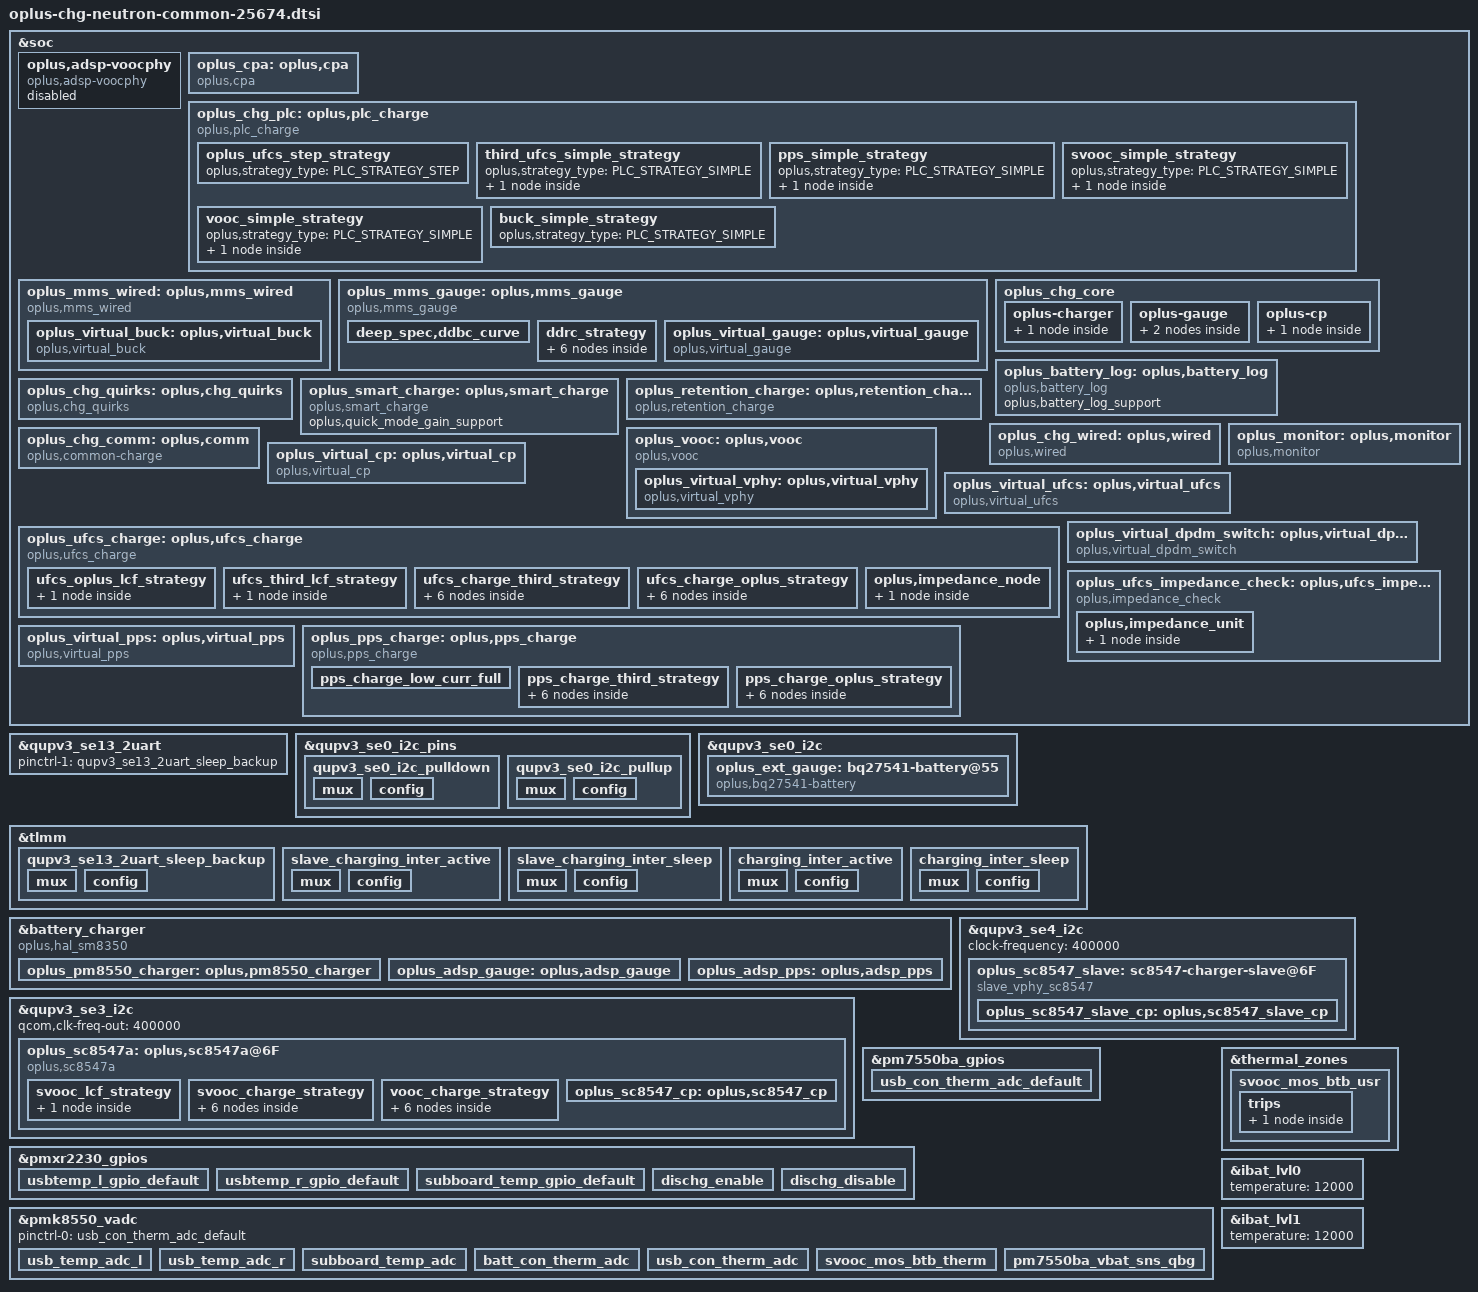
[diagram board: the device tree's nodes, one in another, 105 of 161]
//ifdef OPLUS_FEATURE_CHG_BASIC
#include "../oplus-chg-8750.h.dtsi"
#include <dt-bindings/iio/qcom,spmi-adc5-gen3-pm7550ba.h>
#include <dt-bindings/iio/qcom,spmi-adc5-gen3-pmxr2230.h>

&soc {
	oplus,adsp-voocphy {
		status = "disabled";
		compatible = "oplus,adsp-voocphy";
	};

	oplus_cpa: oplus,cpa {
		compatible = "oplus,cpa";
		oplus,protocol_list = <CHG_PROTOCOL_VOOC 80
				CHG_PROTOCOL_PPS  33
				CHG_PROTOCOL_PD   15
				CHG_PROTOCOL_QC   15>;
		oplus,default_protocol_list = <CHG_PROTOCOL_VOOC
					CHG_PROTOCOL_PPS
					CHG_PROTOCOL_PD>;
	};

	oplus_chg_plc: oplus,plc_charge {
		compatible = "oplus,plc_charge";
		oplus,plc_soc = <90>;
		oplus,plc_strategy-data = <&buck_simple_strategy>;
		oplus,plc_strategy-names = "default";

		oplus_ufcs_step_strategy: oplus_ufcs_step_strategy {
			oplus,strategy_type = <PLC_STRATEGY_STEP>;
		};

		third_ufcs_simple_strategy: third_ufcs_simple_strategy {
			oplus,strategy_type = <PLC_STRATEGY_SIMPLE>;
			oplus,strategy_data {
				strategy_curr_ma = <1000 1500>;
			};
		};

		pps_simple_strategy: pps_simple_strategy {
			oplus,strategy_type = <PLC_STRATEGY_SIMPLE>;
			oplus,strategy_data {
				strategy_curr_ma = <1000 1500>;
			};
		};

		svooc_simple_strategy: svooc_simple_strategy {
			oplus,strategy_type = <PLC_STRATEGY_SIMPLE>;
			oplus,strategy_data {
				strategy_curr_ma = <1000 1500>;
			};
		};

		vooc_simple_strategy: vooc_simple_strategy {
			oplus,strategy_type = <PLC_STRATEGY_SIMPLE>;
			oplus,strategy_data {
				strategy_curr_ma = <2000 3000>;
			};
		};


		buck_simple_strategy: buck_simple_strategy {
			oplus,strategy_type = <PLC_STRATEGY_SIMPLE>;
		};
	};

	oplus_mms_wired: oplus,mms_wired {
		compatible = "oplus,mms_wired";
		oplus,buck_ic = <&oplus_virtual_buck>;
		oplus,voocphy_ic = <&oplus_virtual_vphy>;
		oplus,adc_info_name = "855";
		oplus,topic-update-interval = <5000>;
		high-temp-scheme;
		oplus,otg_cc_limit = <80 2000     /* 100~80 >=80 2A   */
		                      20 1500     /* 80~20  >=20 1.5A */
		                      1  1300>;   /* 20~1   >=1  1.3A */
		oplus,support_usbtemp_protect_v2;
		oplus_spec,usbtemp_batt_temp_low = <50>;
		oplus_spec,usbtemp_batt_temp_high = <50>;
		oplus_spec,usbtemp_batt_temp_over_hot = <60>;
		oplus_spec,usbtemp_ntc_temp_low = <57>;
		oplus_spec,usbtemp_ntc_temp_high = <69>;
		oplus_spec,usbtemp_temp_gap_low_with_batt_temp = <7>;
		oplus_spec,usbtemp_temp_gap_with_batt_temp_in_over_hot = <15>;
		oplus_spec,usbtemp_temp_gap_high_with_batt_temp = <12>;
		oplus_spec,usbtemp_temp_gap_low_without_batt_temp = <12>;
		oplus_spec,usbtemp_temp_gap_high_without_batt_temp = <24>;
		oplus_spec,usbtemp_rise_fast_temp_low = <3>;
		oplus_spec,usbtemp_rise_fast_temp_high = <3>;
		oplus_spec,usbtemp_rise_fast_temp_count_low = <30>;
		oplus_spec,usbtemp_rise_fast_temp_count_high = <20>;
		oplus_spec,usbtemp_cool_down_ntc_low = <54>;
		oplus_spec,usbtemp_cool_down_ntc_high = <65>;
		oplus_spec,usbtemp_cool_down_gap_low = <12>;
		oplus_spec,usbtemp_cool_down_gap_high = <20>;
		oplus_spec,usbtemp_cool_down_recover_ntc_low = <48>;
		oplus_spec,usbtemp_cool_down_recover_ntc_high = <60>;
		oplus_spec,usbtemp_cool_down_recover_gap_low = <6>;
		oplus_spec,usbtemp_cool_down_recover_gap_high = <15>;
		oplus_spec,usbtemp_otg_cc_boot_current_limit = <2000>;

		oplus_virtual_buck: oplus,virtual_buck {
			compatible = "oplus,virtual_buck";
			oplus,buck_ic = <&oplus_pm8550_charger>;
			oplus,buck_ic_index = <0>;
			oplus,buck_ic_connect = <OPLUS_CHG_IC_CONNECT_PARALLEL>;
			oplus,main_charger = <0>;
			oplus,buck_ic_current_ratio = <100>;
			oplus,buck_ic_func_group = <&plat_pm8550_groups>;

			oplus,ic_type = <OPLUS_CHG_IC_VIRTUAL_BUCK>;
			oplus,ic_index = <0>;

			oplus,dischg-gpio = <&pmxr2230_gpios 9 0x00>;
			oplus,usbtemp_conversion_ratio = <10>;

			pinctrl-names = "usbtemp_l_gpio_default", "usbtemp_r_gpio_default",
					"dischg_enable", "dischg_disable";
			pinctrl-0 = <&usbtemp_l_gpio_default>;
			pinctrl-1 = <&usbtemp_r_gpio_default>;
			pinctrl-2 = <&dischg_enable>;
			pinctrl-3 = <&dischg_disable>;

			io-channels = <&pmk8550_vadc PMXR2230_ADC5_GEN3_AMUX1_GPIO3_100K_PU>,
					<&pmk8550_vadc PMXR2230_ADC5_GEN3_AMUX2_GPIO4_100K_PU>;
			io-channel-names = "usb_temp_adc_l", "usb_temp_adc_r";

			oplus,uart_tx-gpio = <&tlmm 18 0x00>;
			oplus,uart_rx-gpio = <&tlmm 19 0x00>;
		};
	};

	oplus_mms_gauge: oplus,mms_gauge {
		compatible = "oplus,mms_gauge";
		oplus,gauge_ic = <&oplus_virtual_gauge>;
		oplus,voocphy_ic = <&oplus_virtual_vphy>;
		oplus,topic-update-interval = <5000>;
		oplus,support_subboard_ntc;

		deep_spec,support;
		deep_spec,uv_thr = <3000>;
		deep_spec,count_thr = <50>;
		deep_spec,vbat_soc = <20>;
		deep_spec,count_step = <0 10 0
					350 12 1
					450 15 2
					530 20 3>;

		deep_spec,term_coeff = <3000 320 0
					3050 440 2
					3060 440 2
					3100 540 4
					3200 580 5
					3300 600 7>;
		deep_spec,ddrc_strategy_name = "ddrc_curve";
		deep_spec,volt_step = <20>;
		deep_spec,ddbc_curve {
			oplus,temp_type = <OPLUS_STRATEGY_USE_BATT_TEMP>;
			oplus,temp_range = <(-100) 50 200>;
			deep_spec,ddbc_temp_cold = <500 3250 5
						   10000 3200 2>;
			deep_spec,ddbc_temp_cool = <500 3250 5
						   10000 3200 2>;
			deep_spec,ddbc_temp_normal = <500 3350 5
						   10000 3300 2>;
			deep_spec,ddbc_temp_warm = <500 3350 5
						   10000 3300 2>;
		};

		ddrc_strategy {
			oplus,temp_type = <OPLUS_STRATEGY_USE_BATT_TEMP>;
			oplus,ratio_range = <20 30 50 70 90>;
			oplus,temp_range = <(-50) 100 350>;
			strategy_ratio_range_min {
				strategy_temp_cold =	<0 3000 3060 0
							400 3000 3060 1
							800 3000 3060 2
							1200 3100 3100 3
							1600 3200 3200 4
							2000 3300 3300 5>;
				strategy_temp_cool =	<0 3000 3060 0
							15   3000 3060 1
							500  3000 3060 2
							1000 3100 3100 3
							1500 3200 3200 4
							2000 3300 3300 5>;
				strategy_temp_normal =	<0 3100 3100 0
							15   3000 3060 1
							500  3100 3100 2
							1000 3200 3200 3
							1500 3300 3300 4>;
				strategy_temp_warm =	<0 3100 3100 0
							15   3000 3060 1
							500  3100 3100 2
							1000 3200 3200 3
							1500 3300 3300 4>;
			};
			strategy_ratio_range_low {
				strategy_temp_cold =	<0 3000 3060 0
							300 3000 3060 1
							600 3000 3060 2
							900 3100 3100 3
							1200 3200 3200 4
							1600 3300 3300 5>;
				strategy_temp_cool =	<0 3000 3060 0
							15   3000 3060 1
							400  3000 3060 2
							800  3100 3100 3
							1200 3200 3200 4
							1600 3300 3300 5>;
				strategy_temp_normal =	<0 3100 3100 0
							15   3000 3060 1
							400  3100 3100 2
							800  3200 3200 3
							1200 3300 3300 4>;
				strategy_temp_warm =	<0 3100 3100 0
							15   3000 3060 1
							400  3100 3100 2
							800  3200 3200 3
							1200 3300 3300 4>;
			};
			strategy_ratio_range_mid_low {
				strategy_temp_cold =	<0 3000 3060 0
							200   3000 3060 1
							400  3100 3060 2
							600  3100 3100 3
							900 3200 3200 4
							1200 3300 3300 5>;
				strategy_temp_cool =	<0 3000 3060 0
							15   3000 3060 1
							300  3000 3060 2
							600  3100 3100 3
							900  3200 3200 4
							1200 3300 3300 5>;
				strategy_temp_normal =	<0 3100 3100 0
							15  3100 3100 1
							300 3100 3100 2
							600 3200 3200 3
							900 3300 3300 4>;
				strategy_temp_warm =	<0 3100 3100 0
							15  3100 3100 1
							300 3100 3100 2
							600 3200 3200 3
							900 3300 3300 4>;
			};
			strategy_ratio_range_mid {
				strategy_temp_cold =	<0 3000 3060 0
							100   3000 3060 1
							300  3000 3060 2
							500  3100 3100 3
							700 3200 3200 4
							900 3300 3300 5>;
				strategy_temp_cool =	<0 3000 3060 0
							100 3000 3060 1
							300 3100 3100 2
							600 3200 3200 3
							900 3300 3300 4>;
				strategy_temp_normal =	<0 3100 3100 0
							100 3100 3100 1
							300 3200 3200 2
							600 3300 3300 3>;
				strategy_temp_warm =	<0 3100 3100 0
							100 3100 3100 1
							300 3200 3200 2
							600 3300 3300 3>;
			};
			strategy_ratio_range_mid_high {
				strategy_temp_cold =	<0 3000 3060 0
							50  3000 3060 1
							100 3000 3060 2
							150 3100 3100 3
							300 3200 3200 4
							500 3300 3300 5>;
				strategy_temp_cool =	<0 3000 3060 0
							50  3000 3060 1
							100 3100 3100 2
							150 3200 3200 3
							300 3300 3300 4>;
				strategy_temp_normal =	<0 3100 3100 0
							50  3100 3100 1
							100 3200 3200 2
							150 3300 3300 3>;
				strategy_temp_warm =	<0 3100 3100 0
							50  3100 3100 1
							100 3200 3200 2
							150 3300 3300 3>;
			};
			strategy_ratio_range_high {
				strategy_temp_cold =	<0 3000 3060 0
                                                        50  3000 3060 1
                                                        100 3000 3060 2
                                                        150 3100 3100 3
                                                        300 3200 3200 4
                                                        500 3300 3300 5>;
				strategy_temp_cool =	<0 3000 3060 0
							50  3000 3060 1
							100 3100 3100 2
							150 3200 3200 3
							300 3300 3300 4>;
				strategy_temp_normal =	<0 3100 3100 0
							50  3100 3100 1
							100 3200 3200 2
							150 3300 3300 3>;
				strategy_temp_warm =	<0 3100 3100 0
							50  3100 3100 1
							100 3200 3200 2
							150 3300 3300 3>;
			};
		};

		oplus_virtual_gauge: oplus,virtual_gauge {
			compatible = "oplus,virtual_gauge";
			oplus,gauge_ic = <&oplus_ext_gauge &oplus_adsp_gauge>;
			oplus,gauge_ic_index = <0 1>;
			oplus,gauge_ic_func_group = <&bq27541_groups &adsp_gauge_groups>;
			oplus,batt_capacity_mah = <7000>;
			oplus,ic_type = <OPLUS_CHG_IC_VIRTUAL_GAUGE>;
			oplus,ic_index = <0>;
		};
	};

	oplus_chg_core: oplus_chg_core {
		oplus,chg_framework_v2;
		oplus,battery_type_by_smem;
		oplus,smart_charging_screenoff;
		oplus,chg_spec_version = <OPLUS_CHG_SPEC_VER_V3P7>;
		oplus,eco_region_list = /bits/ 8 <0x44>;
		oplus,common-charge-icl-support;

		oplus-charger {
			plat_pm8550_groups: oplus,plat_pm8550-groups {
				functions = <
					OPLUS_IC_FUNC_INIT
					OPLUS_IC_FUNC_EXIT
					OPLUS_IC_FUNC_REG_DUMP
					OPLUS_IC_FUNC_SMT_TEST
					OPLUS_IC_FUNC_BUCK_INPUT_PRESENT
					OPLUS_IC_FUNC_BUCK_INPUT_SUSPEND
					OPLUS_IC_FUNC_BUCK_INPUT_IS_SUSPEND
					OPLUS_IC_FUNC_BUCK_OUTPUT_SUSPEND
					OPLUS_IC_FUNC_BUCK_OUTPUT_IS_SUSPEND
					OPLUS_IC_FUNC_BUCK_GET_CC_ORIENTATION
					OPLUS_IC_FUNC_BUCK_GET_CHARGER_TYPE
					OPLUS_IC_FUNC_BUCK_RERUN_BC12
					OPLUS_IC_FUNC_BUCK_QC_DETECT_ENABLE
					OPLUS_IC_FUNC_BUCK_SHIPMODE_ENABLE
					OPLUS_IC_FUNC_BUCK_SET_QC_CONFIG
					OPLUS_IC_FUNC_BUCK_SET_PD_CONFIG
					OPLUS_IC_FUNC_GET_SHUTDOWN_SOC
					OPLUS_IC_FUNC_BACKUP_SOC
					OPLUS_IC_FUNC_GET_TYPEC_MODE
					OPLUS_IC_FUNC_BUCK_SET_ICL
					OPLUS_IC_FUNC_BUCK_GET_ICL
					OPLUS_IC_FUNC_BUCK_SET_FCC
					OPLUS_IC_FUNC_BUCK_SET_FV
					OPLUS_IC_FUNC_BUCK_SET_ITERM
					OPLUS_IC_FUNC_BUCK_SET_RECHG_VOL
					OPLUS_IC_FUNC_BUCK_GET_INPUT_CURR
					OPLUS_IC_FUNC_BUCK_GET_INPUT_VOL
					OPLUS_IC_FUNC_GET_CHARGER_CYCLE
					OPLUS_IC_FUNC_OTG_BOOST_ENABLE
					OPLUS_IC_FUNC_SET_OTG_BOOST_CURR_LIMIT
					OPLUS_IC_FUNC_SET_OTG_SRC_PDO
					OPLUS_IC_FUNC_BUCK_GET_VBUS_COLLAPSE_STATUS
					OPLUS_IC_FUNC_GET_OTG_ENABLE
					OPLUS_IC_FUNC_SET_OTG_SWITCH_STATUS
					OPLUS_IC_FUNC_GET_OTG_SWITCH_STATUS
					OPLUS_IC_FUNC_GET_OTG_ONLINE_STATUS
					OPLUS_IC_FUNC_BUCK_GET_HW_DETECT
					OPLUS_IC_FUNC_VOOCPHY_SET_MATCH_TEMP
					OPLUS_IC_FUNC_IS_OPLUS_SVID
					OPLUS_IC_FUNC_BUCK_SET_VINDPM
					OPLUS_IC_FUNC_BUCK_DIS_INSERT_DETECT
					OPLUS_IC_FUNC_GET_TYPEC_ROLE
					OPLUS_IC_FUNC_SET_TYPEC_MODE
					OPLUS_IC_FUNC_BUCK_GET_USB_BTB_TEMP
					OPLUS_IC_FUNC_BUCK_GET_BATT_BTB_TEMP
					OPLUS_IC_FUNC_BUCK_GET_TYPEC_STATE
				>;
				virqs = <
					OPLUS_IC_VIRQ_ERR
					OPLUS_IC_VIRQ_CC_DETECT
					OPLUS_IC_VIRQ_PLUGIN
					OPLUS_IC_VIRQ_CC_CHANGED
					OPLUS_IC_VIRQ_SUSPEND_CHECK
					OPLUS_IC_VIRQ_CHG_TYPE_CHANGE
					OPLUS_IC_VIRQ_OTG_ENABLE
					OPLUS_IC_VIRQ_SVID
				>;
			};
		};

		oplus-gauge {
			bq27541_groups: oplus,bq27541_groups {
				functions = <
					OPLUS_IC_FUNC_INIT
					OPLUS_IC_FUNC_EXIT
					OPLUS_IC_FUNC_REG_DUMP
					OPLUS_IC_FUNC_SMT_TEST
					OPLUS_IC_FUNC_GAUGE_GET_BATT_VOL
					OPLUS_IC_FUNC_GAUGE_GET_BATT_MAX
					OPLUS_IC_FUNC_GAUGE_GET_BATT_MIN
					OPLUS_IC_FUNC_GAUGE_GET_BATT_CURR
					OPLUS_IC_FUNC_GAUGE_GET_BATT_TEMP
					OPLUS_IC_FUNC_GAUGE_GET_BATT_SOC
					OPLUS_IC_FUNC_GAUGE_GET_BATT_FCC
					OPLUS_IC_FUNC_GAUGE_GET_BATT_CC
					OPLUS_IC_FUNC_GAUGE_GET_BATT_RM
					OPLUS_IC_FUNC_GAUGE_GET_BATT_SOH
					OPLUS_IC_FUNC_GAUGE_GET_BATT_AUTH
					OPLUS_IC_FUNC_GAUGE_GET_BATT_HMAC
					OPLUS_IC_FUNC_GAUGE_SET_BATT_FULL
					OPLUS_IC_FUNC_GAUGE_UPDATE_DOD0
					OPLUS_IC_FUNC_GAUGE_UPDATE_SOC_SMOOTH
					OPLUS_IC_FUNC_GAUGE_GET_CB_STATUS
					OPLUS_IC_FUNC_GAUGE_GET_BATT_NUM
					OPLUS_IC_FUNC_GAUGE_GET_DEVICE_TYPE
					OPLUS_IC_FUNC_GAUGE_GET_DEVICE_TYPE_FOR_VOOC
					OPLUS_IC_FUNC_GAUGE_GET_BATT_FCC
					OPLUS_IC_FUNC_GAUGE_GET_BATT_FC
					OPLUS_IC_FUNC_GAUGE_GET_BATT_QM
					OPLUS_IC_FUNC_GAUGE_GET_BATT_PD
					OPLUS_IC_FUNC_GAUGE_GET_BATT_RCU
					OPLUS_IC_FUNC_GAUGE_GET_BATT_RCF
					OPLUS_IC_FUNC_GAUGE_GET_BATT_FCU
					OPLUS_IC_FUNC_GAUGE_GET_BATT_FCF
					OPLUS_IC_FUNC_GAUGE_GET_BATT_SOU
					OPLUS_IC_FUNC_GAUGE_GET_BATT_DO0
					OPLUS_IC_FUNC_GAUGE_GET_BATT_DOE
					OPLUS_IC_FUNC_GAUGE_GET_BATT_TRM
					OPLUS_IC_FUNC_GAUGE_GET_BATT_PC
					OPLUS_IC_FUNC_GAUGE_GET_BATT_QS
					OPLUS_IC_FUNC_GAUGE_IS_SUSPEND
					OPLUS_IC_FUNC_GAUGE_GET_BCC_PARMS
					OPLUS_IC_FUNC_GAUGE_FASTCHG_UPDATE_BCC_PARMS
					OPLUS_IC_FUNC_GAUGE_GET_PREV_BCC_PARMS
					OPLUS_IC_FUNC_GAUGE_SET_BCC_PARMS
					OPLUS_IC_FUNC_GAUGE_SET_PROTECT_CHECK
					OPLUS_IC_FUNC_GAUGE_GET_AFI_UPDATE_DONE
					OPLUS_IC_FUNC_GAUGE_CHECK_RESET
					OPLUS_IC_FUNC_GAUGE_SET_RESET
					OPLUS_IC_FUNC_GAUGE_GET_DEVICE_TYPE_FOR_BCC
					OPLUS_IC_FUNC_GAUGE_GET_DOD0
					OPLUS_IC_FUNC_GAUGE_GET_DOD0_PASSED_Q
					OPLUS_IC_FUNC_GAUGE_GET_QMAX
					OPLUS_IC_FUNC_GAUGE_GET_QMAX_PASSED_Q
					OPLUS_IC_FUNC_GAUGE_GET_REG_INFO
					OPLUS_IC_FUNC_GAUGE_GET_CALIB_TIME
					OPLUS_IC_FUNC_GAUGE_GET_DEEP_DISCHG_COUNT
					OPLUS_IC_FUNC_GAUGE_SET_DEEP_DISCHG_COUNT
					OPLUS_IC_FUNC_GAUGE_GET_DEEP_TERM_VOLT
					OPLUS_IC_FUNC_GAUGE_SET_DEEP_TERM_VOLT
					OPLUS_IC_FUNC_GAUGE_SET_SILI_SPARE_POWER
					OPLUS_IC_FUNC_GAUGE_GET_SILI_SIMULATE_TERM_VOLT
					OPLUS_IC_FUNC_GAUGE_GET_SILI_IC_ALG_TERM_VOLT
					OPLUS_IC_FUNC_GAUGE_SET_SILI_IC_ALG_CFG
					OPLUS_IC_FUNC_GAUGE_GET_SILI_IC_ALG_DSG_ENABLE
					OPLUS_IC_FUNC_GAUGE_SET_SILI_IC_ALG_TERM_VOLT
					OPLUS_IC_FUNC_GAUGE_GET_SILI_ALG_APPLICATION_INFO
					OPLUS_IC_FUNC_GAUGE_GET_SILI_LIFETIME_STATUS
					OPLUS_IC_FUNC_GAUGE_GET_SILI_LIFETIME_INFO
					OPLUS_IC_FUNC_GAUGE_SET_LAST_CC
					OPLUS_IC_FUNC_GAUGE_GET_LAST_CC
					OPLUS_IC_FUNC_GAUGE_GET_CHEM_ID
					OPLUS_IC_FUNC_GAUGE_GET_DEC_FG_TYPE
					OPLUS_IC_FUNC_GAUGE_GET_DEC_CV_SOH
					OPLUS_IC_FUNC_GAUGE_SET_VCT
					OPLUS_IC_FUNC_GAUGE_GET_VCT
				>;
				virqs = <
					OPLUS_IC_VIRQ_ERR
					OPLUS_IC_VIRQ_OFFLINE
					OPLUS_IC_VIRQ_RESUME
				>;
			};
			adsp_gauge_groups: oplus,gauge_groups {
				functions = <
					OPLUS_IC_FUNC_INIT
					OPLUS_IC_FUNC_EXIT
					OPLUS_IC_FUNC_REG_DUMP
					OPLUS_IC_FUNC_SMT_TEST
					OPLUS_IC_FUNC_GAUGE_GET_SUBBOARD_TEMP
				>;
				virqs = <
					OPLUS_IC_VIRQ_ERR
				>;
			};
		};

		oplus-cp {
			sc8547_cp_groups: oplus,cp_groups {
			functions = <
					OPLUS_IC_FUNC_INIT
					OPLUS_IC_FUNC_EXIT
					OPLUS_IC_FUNC_REG_DUMP
					OPLUS_IC_FUNC_SMT_TEST
					OPLUS_IC_FUNC_CP_ENABLE
					OPLUS_IC_FUNC_CP_HW_INTI
					OPLUS_IC_FUNC_CP_SET_WORK_START
					OPLUS_IC_FUNC_CP_CHECK_WORK_MODE_SUPPORT
					OPLUS_IC_FUNC_CP_SET_WORK_MODE
					OPLUS_IC_FUNC_CP_GET_WORK_MODE
					OPLUS_IC_FUNC_CP_GET_VIN
					OPLUS_IC_FUNC_CP_GET_IIN
					OPLUS_IC_FUNC_CP_SET_IIN
					OPLUS_IC_FUNC_CP_GET_VOUT
					OPLUS_IC_FUNC_CP_GET_IOUT
					OPLUS_IC_FUNC_CP_GET_VAC
					OPLUS_IC_FUNC_CP_GET_WORK_STATUS
					OPLUS_IC_FUNC_CP_SET_ADC_ENABLE
					OPLUS_IC_FUNC_CP_WATCHDOG_ENABLE
				>;
				virqs = <
					OPLUS_IC_VIRQ_ERR
					OPLUS_IC_VIRQ_ONLINE
					OPLUS_IC_VIRQ_OFFLINE
				>;
			};
		};
	};

	oplus_battery_log: oplus,battery_log {
		compatible = "oplus,battery_log";

		oplus,battery_log_support;
	};

	oplus_chg_quirks: oplus,chg_quirks {
		compatible = "oplus,chg_quirks";
	};

	oplus_smart_charge: oplus,smart_charge {
		compatible = "oplus,smart_charge";
		oplus,quick_mode_gain_support;
	};

	oplus_retention_charge: oplus,retention_charge {
		compatible = "oplus,retention_charge";
		oplus,topic-update-interval = <5000>;
		oplus,support_retention_name = "oplus_retention_quirks";
	};

	oplus_chg_wired: oplus,wired {
		compatible = "oplus,wired";

		oplus,vooc-support;

		oplus_spec,vbatt_pdqc_to_5v_thr = <5100>;
		oplus_spec,vbatt_pdqc_to_9v_thr = <5000>;
		oplus_spec,pd-iclmax-ma = <1500>;
		oplus_spec,qc-iclmax-ma = <1500>;
		oplus_spec,non-standard-ibatmax-ma = <500>;
		oplus_spec,input-power-mw = <
			2500		/* OPLUS_WIRED_CHG_MODE_UNKNOWN */
			2500		/* OPLUS_WIRED_CHG_MODE_SDP */
			7500		/* OPLUS_WIRED_CHG_MODE_CDP */
			10000		/* OPLUS_WIRED_CHG_MODE_DCP */
			15000		/* OPLUS_WIRED_CHG_MODE_VOOC */
			13500		/* OPLUS_WIRED_CHG_MODE_QC */
			13500		/* OPLUS_WIRED_CHG_MODE_PD */
		>;
		oplus_spec,led_on-fccmax-ma = <0 614 3073 3850 3850 3850 3850 1000 0>;
		oplus_spec,fccmax-ma-lv = <
			0 1761 2200 2200 2200 2200 2200 2200 0	/* OPLUS_WIRED_CHG_MODE_UNKNOWN */
			0 600  600  600  600  600  600  600  0	/* OPLUS_WIRED_CHG_MODE_SDP */
			0 614  1600 1600 1600 1600 1600 1600 0	/* OPLUS_WIRED_CHG_MODE_CDP */
			0 614  2200 2200 2200 2200 2200 2200 0	/* OPLUS_WIRED_CHG_MODE_DCP */
			0 1200 3600 3600 3600 3600 2200 2200 0	/* OPLUS_WIRED_CHG_MODE_VOOC */
			0 614  3073 3300 3300 3300 3300 3300 0	/* OPLUS_WIRED_CHG_MODE_QC */
			0 614  3073 3300 3300 3300 3300 3300 0	/* OPLUS_WIRED_CHG_MODE_PD */
		>;
		oplus_spec,fccmax-ma-hv = <
			0 1761 2200 2200 2200 2200 2200 2200 0	/* OPLUS_WIRED_CHG_MODE_UNKNOWN */
			0 600  600  600  600  600  600  600  0	/* OPLUS_WIRED_CHG_MODE_SDP */
			0 614  1229 1600 1600 1600 1600 1600 0	/* OPLUS_WIRED_CHG_MODE_CDP */
			0 614  1229 1844 2200 2200 2200 2200 0	/* OPLUS_WIRED_CHG_MODE_DCP */
			0 1200 3600 3600 3600 3600 2200 2200 0	/* OPLUS_WIRED_CHG_MODE_VOOC */
			0 614  1229 1844 3073 3300 3300 3300 0	/* OPLUS_WIRED_CHG_MODE_QC */
			0 614  1229 1844 3073 3300 3300 3300 0	/* OPLUS_WIRED_CHG_MODE_PD */
		>;

		oplus_spec,cool_down_sale_pdqc_vol_mv = <5000>;
		oplus_spec,cool_down_sale_pdqc_curr_ma = <1200>;
		oplus_spec,cool_down_pdqc_vol_mv = <9000 9000 9000>;
		oplus_spec,cool_down_pdqc_curr_ma = <1200 1500 1500>;
		oplus_spec,cool_down_vooc_curr_ma = <1200 1500 2000 2500 3000 3000>;
		oplus_spec,cool_down_normal_curr_ma = <1200 1500 2000>;

		oplus_spec,vbus_ov_thr_mv = <10000 10000>;
		oplus_spec,vbus_uv_thr_mv = <4300 4300>;

		/* first data is strategy used temp type */
		oplus,pd_strategy_name = "cgcl";
		oplus,pd_strategy_data = <OPLUS_STRATEGY_USE_SHELL_TEMP
					    0   420 2000 1 0
					    410 430 1500 2 0
					    420 440 1200 2 1>;
		oplus,qc_strategy_name = "cgcl";
		oplus,qc_strategy_data = <OPLUS_STRATEGY_USE_SHELL_TEMP
					    0   420 2000 1 0
					    410 430 1500 2 0
					    420 440 1200 2 1>;
	};

	oplus_chg_comm: oplus,comm {
		compatible = "oplus,common-charge";
		oplus_spec,dec_step = <20>;
		oplus_spec,dec-vol-cc-full-thr = <0 400 600 800 1000 1200>;
		oplus_spec,dec-vol-fv-full-mv = <0 20 20 40 40 40>;
		oplus_spec,batt-them-thr = <(-100) 0 50 120 160 350 450 530>;
		oplus_spec,removed_bat_decidegc = <390>; /*-39 degree*/
		oplus_spec,iterm-ma = <352>; /* 2220*0.05+10 */
		oplus_spec,fv-mv = <4500 4500 4500 4500 4500 4500 4475 4130 4130>;
		oplus_spec,sw-fv-mv = <4450 4450 4450 4450 4450 4450 4425 4080 4080>;
		oplus_spec,hw-fv-inc-mv = <0 18 18 18 18 18 18 18 0>;
		oplus_spec,sw-over-fv-mv = <4510 4510 4510 4510 4510 4510 4485 4140 4140>;
		oplus_spec,sw-over-fv-dec-mv = <8>;
		oplus_spec,non-standard-sw-fv-mv = <3930>;
		oplus_spec,non-standard-fv-mv = <3980>;
		oplus_spec,non-standard-hw-fv-inc-mv = <18>;
		oplus_spec,non-standard-sw-over-fv-mv = <3990>;
		oplus_spec,non-standard-vbatdet-mv = <3680>;
		oplus_spec,wired-vbatdet-mv = <0 4200 4300 4400 4400 4400 4375 4030 0>;
		oplus_spec,fcc-gear-thr-mv = <4180>;
		oplus_spec,fcc-gear-shake-mv = <400 400 400 300 300 180 180 180 180>;
		oplus_spec,vbatt-ov-thr-mv = <4600>;
		oplus_spec,full_pre_ffc_judge;
		oplus_spec,full-pre-ffc-mv = <4495>;
		oplus_spec,ffc-temp-thr = <120 210 350 440>;
		oplus_spec,wired-ffc-step-max = <2>;
		oplus_spec,wired-ffc-fv-mv = <4630 4630>;

		oplus_spec,wired-ffc-fv-cutoff-mv = <4565 4565 4510 4565 4565 4500>;
		oplus_spec,wired-ffc-fcc-ma = <1500 1700 1500 1200 1600 1000>;
		oplus_spec,wired-ffc-fcc-cutoff-ma = <1300 1500 1300 1100 1400 900>;

		oplus,ui_soc_2_voltage_comp_mv = <30>;
		oplus_spec,drop_soc_2_temp_ladder = <(-50) 0 0 0 0 0 0 0 0 0>;
		oplus_spec,volt_diff_ladder_of_drop_soc_2 = <80 80 0 0 0 0 0 0 0 0>;
		oplus_spec,keep_soc_2_temp_ladder = <(-200) (-50) 0 0 0 0 0 0 0 0>;
		oplus_spec,volt_diff_ladder_of_keep_soc_2 = <10 20 30 0 0 0 0 0 0 0>;
		oplus_spec,back_rm_of_drop_soc_2 = <60>;
		oplus_spec,back_rm_of_drop_soc_1 = <60>;
		oplus_spec,load_current_of_drop_soc_2 = <500>;
		oplus_spec,load_current_of_drop_soc_1 = <1000>;
		oplus_spec,current_limit_of_drop_soc_2 = <350>;
		oplus_spec,volt_of_fast_drop_soc_1 = <2900>;
		oplus_spec,support_uisoc_low_battery_control;
		oplus_spec,vbat_uv_thr_mv = <3100>;
		oplus_spec,vbat_charging_uv_thr_mv = <3000>;

		/*If use subboard NTC as battery temp, config it as 20, otherwise 0 */
		oplus_spec,tbatt_power_off_cali_temp = <0>;
		oplus,vooc_show_ui_soc_decimal;
		oplus,ui_soc_decimal_speedmin = <20>;
		oplus_spec,poweroff_high_batt_temp = <720>;
		oplus_spec,poweroff_emergency_batt_temp = <770>;
		oplus,gauge_stuck_jump_support;
		oplus,gauge_stuck_threshold = <15>;
		oplus,gauge_stuck_time = <50>;
		oplus_spec,pm_power_off_with_hightemp;
	};

	oplus_monitor: oplus,monitor {
		compatible = "oplus,monitor";
		oplus,topic-update-interval = <60000>;

		track,fast_chg_break_t_thd = <1400>;
		track,general_chg_break_t_thd = <300>;
		track,voocphy_type = <3>;
		track,wired_max_power = <80000>;
		track,wired_fast_chg_scheme = <2>;

		track,gauge_status_ctrl;
		track,external_gauge_num = <1>;
	};

	oplus_vooc: oplus,vooc {
		compatible = "oplus,vooc";
		oplus,vooc_ic = <&oplus_virtual_vphy>;

		oplus_spec,vooc_soc_range = <50 75 85>;

		oplus,vooc_data_width = <7>;
		oplus,vooc_curr_max = <CP_CURR_LIMIT_7BIT_15_0A>; /* 80W: 11V 7.3A(IBUS *2) */
		oplus,vooc_power_max_w = <80>;
		oplus,vooc_project = <7>;
		oplus,vooc_curr_table_type = <VOOC_CP_CURR_TABLE>;
		oplus,voocphy_support = <3>; /* AP_DUAL_CP_VOOCPHY */
		oplus,support_fake_vooc_check;
		oplus,subboard_ntc_abnormal_current = <4000>;
		oplus,smart_chg_bcc_support;

		oplus,abnormal_adapter_current = <CP_CURR_LIMIT_7BIT_15_0A CP_CURR_LIMIT_7BIT_15_0A
						CP_CURR_LIMIT_7BIT_10_0A CP_CURR_LIMIT_7BIT_10_0A
						CP_CURR_LIMIT_7BIT_8_0A CP_CURR_LIMIT_7BIT_8_0A
						CP_CURR_LIMIT_7BIT_6_0A CP_CURR_LIMIT_7BIT_6_0A
						CP_CURR_LIMIT_7BIT_4_0A CP_CURR_LIMIT_7BIT_4_0A>;

		oplus,abnormal_over_80w_adapter_current = <CP_CURR_LIMIT_7BIT_15_0A CP_CURR_LIMIT_7BIT_15_0A
						CP_CURR_LIMIT_7BIT_14_0A CP_CURR_LIMIT_7BIT_14_0A
						CP_CURR_LIMIT_7BIT_12_0A CP_CURR_LIMIT_7BIT_12_0A
						CP_CURR_LIMIT_7BIT_10_0A CP_CURR_LIMIT_7BIT_10_0A
						CP_CURR_LIMIT_7BIT_8_0A CP_CURR_LIMIT_7BIT_8_0A
						CP_CURR_LIMIT_7BIT_6_0A CP_CURR_LIMIT_7BIT_6_0A
						CP_CURR_LIMIT_7BIT_4_0A CP_CURR_LIMIT_7BIT_4_0A>;

		/* first data is strategy used temp type */
		oplus,general_strategy_name = "cgcl";
		oplus,general_strategy_data = < OPLUS_STRATEGY_USE_SHELL_TEMP
						0   400 CP_CURR_LIMIT_7BIT_15_0A 1 0
						390 420 CP_CURR_LIMIT_7BIT_8_0A 2 0
						410 430 CP_CURR_LIMIT_7BIT_6_0A 3 1
						420 440 CP_CURR_LIMIT_7BIT_3_0A 3 2>;

		oplus,plc_strategy-data = <&buck_simple_strategy &svooc_simple_strategy &vooc_simple_strategy>;
		oplus,plc_strategy-names = "default", "svooc", "vooc";

		oplus_virtual_vphy: oplus,virtual_vphy {
			compatible = "oplus,virtual_vphy";
			oplus,vphy_ic = <&oplus_sc8547a>;
			oplus,dpdm_switch_ic = <&oplus_virtual_dpdm_switch>;

			oplus,ic_type = <OPLUS_CHG_IC_VIRTUAL_VPHY>;
			oplus,ic_index = <0>;
		};
	};

	oplus_virtual_cp: oplus,virtual_cp {
		compatible = "oplus,virtual_cp";

		oplus,ic_type = <OPLUS_CHG_IC_VIRTUAL_CP>;
		oplus,ic_index = <0>;

		oplus,cp_ic = <&oplus_sc8547_cp &oplus_sc8547_slave_cp>;
		oplus,input_curr_max_ma = <4000 4000>;

		oplus,cp_ic_connect = <OPLUS_CHG_IC_CONNECT_PARALLEL>;
		oplus,main_cp = <0>;

		oplus,reg_proc_node;
	};

	oplus_virtual_ufcs: oplus,virtual_ufcs {
		compatible = "oplus,virtual_ufcs";

		oplus,ic_type = <OPLUS_CHG_IC_VIRTUAL_UFCS>;
		oplus,ic_index = <0>;
	};

	oplus_ufcs_charge: oplus,ufcs_charge {
		compatible = "oplus,ufcs_charge";
		oplus,ufcs_ic = <&oplus_virtual_ufcs>;
		oplus,cp_ic = <&oplus_virtual_cp>;
		oplus,dpdm_switch_ic = <&oplus_virtual_dpdm_switch>;

		oplus,impedance_unit = <&oplus_ufcs_impedance_unit>;

		oplus,target_vbus_mv = <11000>;
		oplus,curr_max_ma = <4000>;

		oplus,ufcs_warm_allow_vol = <4000>;
		oplus,ufcs_warm_allow_soc = <55>;
		oplus,ufcs_strategy_normal_current = <4000>;
		oplus,ufcs_over_high_or_low_current = <4000>;
		oplus,ufcs_timeout_third = <30188>;
		oplus,ufcs_timeout_oplus = <30188>;
		oplus,ufcs_ibat_over_third = <9400>;
		oplus,ufcs_ibat_over_oplus = <9400>;
		oplus,ufcs_full_cool_sw_vbat = <4500>;
		oplus,ufcs_full_normal_sw_vbat = <4500>;
		oplus,ufcs_full_normal_hw_vbat = <4510>;
		oplus,ufcs_full_ffc_vbat = <4520>;
		oplus,ufcs_full_warm_vbat = <4130>;
		oplus,ufcs_full_cool_sw_vbat_third = <4460>;
		oplus,ufcs_full_normal_sw_vbat_third= <4460>;
		oplus,ufcs_full_normal_hw_vbat_third = <4500>;
		oplus,ufcs_current_change_timeout = <100>;
		oplus,ufcs_strategy_batt_high_temp = <410 420 430 400 410 420>;
		oplus,ufcs_strategy_high_current = <2000 2000 2000 3000 3000 3000>;
		oplus,ufcs_little_cool_high_temp = <210>;
		oplus,curve_strategy_name = "pps_ufcs_curve_v2";
		oplus_spec,ufcs_high_soc = <95>;
		oplus,ufcs_charge_strategy_soc = <0 20 35 55 75 85 95>;
		oplus,ufcs_charge_strategy_temp = <50 50 120 160 350 440 510>;

		oplus,plc_strategy-data = <&oplus_ufcs_step_strategy &third_ufcs_simple_strategy>;
		oplus,plc_strategy-names = "default", "third";

		ufcs_oplus_lcf_strategy {
			oplus,temp_type = <OPLUS_STRATEGY_USE_SHELL_TEMP>;
			oplus,temp_range = <0 50 120 160 210 380 440>;

			strategy_temp_range_curves {
				strategy_temp_range_t0 =	<420 4570 0
								 395 4565 0
								 370 4550 0
								 345 4540 0
								 320 4530 1>;
				strategy_temp_range_t1 =	<500 4570 0
								 465 4565 0
								 430 4550 0
								 395 4540 0
								 360 4530 1>;
				strategy_temp_range_t2 =	<650 4570 0
								 605 4565 0
								 560 4550 0
								 515 4540 0
								 470 4530 1>;
				strategy_temp_range_t3 =	<700 4570 0
								 650 4565 0
								 550 4550 0
								 450 4540 0
								 300 4530 1>;
				strategy_temp_range_t4 =	<1300 4570 0
								 1250 4565 0
								 1150 4550 0
								 1050 4540 0
								 900 4530 1>;
				strategy_temp_range_t5 =	<1850 4570 0
								 1800 4565 0
								 1700 4550 0
								 1600 4540 0
								 1450 4530 1>;
			};
		};

		ufcs_third_lcf_strategy {
			oplus,temp_type = <OPLUS_STRATEGY_USE_SHELL_TEMP>;
			oplus,temp_range = <0 50 120 160 210 380 440>;

			strategy_temp_range_curves {
				strategy_temp_range_t0 =	<420 4570 0
								 395 4565 0
								 370 4550 0
								 345 4540 0
								 320 4530 1>;
				strategy_temp_range_t1 =	<500 4570 0
								 465 4565 0
								 430 4550 0
								 395 4540 0
								 360 4530 1>;
				strategy_temp_range_t2 =	<650 4570 0
								 605 4565 0
								 560 4550 0
								 515 4540 0
								 470 4530 1>;
				strategy_temp_range_t3 =	<700 4570 0
								 650 4565 0
								 550 4550 0
								 450 4540 0
								 300 4530 1>;
				strategy_temp_range_t4 =	<1300 4570 0
								 1250 4565 0
								 1150 4550 0
								 1050 4540 0
								 900 4530 1>;
				strategy_temp_range_t5 =	<1850 4570 0
								 1800 4565 0
								 1700 4550 0
								 1600 4540 0
								 1450 4530 1>;
			};
		};
		ufcs_charge_third_strategy {
			oplus,temp_type = <OPLUS_STRATEGY_USE_SHELL_TEMP>;
			oplus,soc_range = <0 20 35 55 75 85 95>;
			oplus,temp_range = <0 50 120 160 210 350 440 510>;

			strategy_soc_range_min {
				strategy_temp_little_cold =	<11000 4200 4000 0 0
								11000 4200 3500 0 0
								11000 4200 3000 0 0
								11000 4480 2900 0 0
								11000 4480 2500 0 0
								11000 4480 2000 0 0
								11000 4480 1500 0 0
								11000 4490 1000 1 0>;
				strategy_temp_cool =		<11000 4480 4000 0 0
								11000 4480 3500 0 0
								11000 4480 3000 0 0
								11000 4480 2500 0 0
								11000 4480 2000 0 0
								11000 4480 1500 0 0
								11000 4490 1000 1 0>;
				strategy_temp_little_cool =	<11000 4480 4000 0 0
								11000 4480 3500 0 0
								11000 4480 3000 0 0
								11000 4480 2500 0 0
								11000 4480 2000 0 0
								11000 4480 1500 0 0
								11000 4490 1000 1 0>;
				strategy_temp_little_cool_high = <11000 4480 4000 0 0
								11000 4480 3500 0 0
								11000 4480 3000 0 0
								11000 4480 2500 0 0
								11000 4480 2000 0 0
								11000 4480 1500 0 0
								11000 4490 1000 1 0>;
				strategy_temp_normal_low =	<11000 4480 4000 0 0
								11000 4480 3500 0 0
								11000 4480 3000 0 0
								11000 4480 2500 0 0
								11000 4480 2000 0 0
								11000 4480 1500 0 0
								11000 4490 1000 1 0>;
				strategy_temp_normal_high =	<11000 4460 4000 0 0
								11000 4460 3500 0 0
								11000 4460 3000 0 0
								11000 4460 2500 0 0
								11000 4460 2000 0 0
								11000 4460 1500 0 0
								11000 4470 1000 1 0>;
				strategy_temp_warm =		<11000 4120 3200 0 0
								11000 4120 3000 0 0
								11000 4120 2500 0 0
								11000 4120 2000 0 0
								11000 4120 1500 0 0
								11000 4130 1000 1 0>;
			};
			strategy_soc_range_low {
				strategy_temp_little_cold =	<11000 4200 4000 0 0
								11000 4200 3500 0 0
								11000 4200 3000 0 0
								11000 4480 2900 0 0
								11000 4480 2500 0 0
								11000 4480 2000 0 0
								11000 4480 1500 0 0
								11000 4490 1000 1 0>;
				strategy_temp_cool =		<11000 4480 4000 0 0
								11000 4480 3500 0 0
								11000 4480 3000 0 0
								11000 4480 2500 0 0
								11000 4480 2000 0 0
								11000 4480 1500 0 0
								11000 4490 1000 1 0>;
				strategy_temp_little_cool =	<11000 4480 4000 0 0
								11000 4480 3500 0 0
								11000 4480 3000 0 0
								11000 4480 2500 0 0
								11000 4480 2000 0 0
								11000 4480 1500 0 0
								11000 4490 1000 1 0>;
				strategy_temp_little_cool_high = <11000 4480 4000 0 0
								11000 4480 3500 0 0
								11000 4480 3000 0 0
								11000 4480 2500 0 0
								11000 4480 2000 0 0
								11000 4480 1500 0 0
								11000 4490 1000 1 0>;
				strategy_temp_normal_low =	<11000 4480 4000 0 0
								11000 4480 3500 0 0
								11000 4480 3000 0 0
								11000 4480 2500 0 0
								11000 4480 2000 0 0
								11000 4480 1500 0 0
								11000 4490 1000 1 0>;
				strategy_temp_normal_high =	<11000 4460 4000 0 0
								11000 4460 3500 0 0
								11000 4460 3000 0 0
								11000 4460 2500 0 0
								11000 4460 2000 0 0
								11000 4460 1500 0 0
								11000 4470 1000 1 0>;
				strategy_temp_warm =		<11000 4120 3200 0 0
								11000 4120 3000 0 0
								11000 4120 2500 0 0
								11000 4120 2000 0 0
								11000 4120 1500 0 0
								11000 4130 1000 1 0>;
			};
			strategy_soc_range_mid_low {
				strategy_temp_little_cold =	<11000 4480 2000 0 0
								11000 4480 1500 0 0
								11000 4490 1000 1 0>;
				strategy_temp_cool =		<11000 4480 2500 0 0
								11000 4480 2000 0 0
								11000 4480 1500 0 0
								11000 4490 1000 1 0>;
				strategy_temp_little_cool =	<11000 4480 3000 0 0
								11000 4480 2500 0 0
								11000 4480 2000 0 0
								11000 4480 1500 0 0
								11000 4490 1000 1 0>;
				strategy_temp_little_cool_high = <11000 4480 3000 0 0
								11000 4480 2500 0 0
								11000 4480 2000 0 0
								11000 4480 1500 0 0
								11000 4490 1000 1 0>;
				strategy_temp_normal_low =	<11000 4480 4000 0 0
								11000 4480 3500 0 0
								11000 4480 3000 0 0
								11000 4480 2500 0 0
								11000 4480 2000 0 0
								11000 4480 1500 0 0
								11000 4490 1000 1 0>;
				strategy_temp_normal_high =	<11000 4460 4000 0 0
								11000 4460 3500 0 0
								11000 4460 3000 0 0
								11000 4460 2500 0 0
								11000 4460 2000 0 0
								11000 4460 1500 0 0
								11000 4470 1000 1 0>;
				strategy_temp_warm =		<11000 4120 3200 0 0
								11000 4120 3000 0 0
								11000 4120 2500 0 0
								11000 4120 2000 0 0
								11000 4120 1500 0 0
								11000 4130 1000 1 0>;
			};
			strategy_soc_range_mid {
				strategy_temp_little_cold =	<11000 4480 1500 0 0
								11000 4490 1000 1 0>;
				strategy_temp_cool =		<11000 4480 1500 0 0
								11000 4490 1000 1 0>;
				strategy_temp_little_cool =	<11000 4480 2000 0 0
								11000 4480 1500 0 0
								11000 4490 1000 1 0>;
				strategy_temp_little_cool_high = <11000 4480 2000 0 0
								11000 4480 1500 0 0
								11000 4490 1000 1 0>;
				strategy_temp_normal_low =	<11000 4480 2000 0 0
								11000 4480 1500 0 0
								11000 4490 1000 1 0>;
				strategy_temp_normal_high =	<11000 4460 2500 0 0
								11000 4460 2000 0 0
								11000 4460 1500 0 0
								11000 4470 1000 1 0>;
				strategy_temp_warm =		<11000 4130 1000 1 0>;
			};
			strategy_soc_range_mid_high {
				strategy_temp_little_cold =	<11000 4490 1000 1 0>;
				strategy_temp_cool =		<11000 4480 1500 0 0
								11000 4490 1000 1 0>;
				strategy_temp_little_cool =	<11000 4480 1500 0 0
								11000 4490 1000 1 0>;
				strategy_temp_little_cool_high = <11000 4480 1500 0 0
								11000 4490 1000 1 0>;
				strategy_temp_normal_low =	<11000 4480 1500 0 0
								11000 4490 1000 1 0>;
				strategy_temp_normal_high =	<11000 4460 1500 0 0
								11000 4470 1000 1 0>;
				strategy_temp_warm =		<11000 4130 1000 1 0>;
			};
			strategy_soc_range_high {
				strategy_temp_little_cold =	<11000 4490 1000 1 0>;
				strategy_temp_cool =		<11000 4490 1000 1 0>;
				strategy_temp_little_cool =	<11000 4490 1000 1 0>;
				strategy_temp_little_cool_high = <11000 4490 1000 1 0>;
				strategy_temp_normal_low =	<11000 4490 1000 1 0>;
				strategy_temp_normal_high =	<11000 4470 1000 1 0>;
				strategy_temp_warm =		<11000 4130 1000 1 0>;
			};
		};

		ufcs_charge_oplus_strategy {
			oplus,temp_type = <OPLUS_STRATEGY_USE_SHELL_TEMP>;
			oplus,soc_range = <0 20 35 55 75 85 95>;
			oplus,temp_range = <0 50 120 160 210 350 440 510>;

			strategy_soc_range_min {
				strategy_temp_little_cold =	<11000 4200 4000 0 0
								11000 4200 3500 0 0
								11000 4200 3000 0 0
								11000 4480 2900 0 0
								11000 4480 2500 0 0
								11000 4480 2000 0 0
								11000 4480 1500 0 0
								11000 4490 1000 1 0>;
				strategy_temp_cool =		<11000 4480 4000 0 0
								11000 4480 3500 0 0
								11000 4480 3000 0 0
								11000 4480 2500 0 0
								11000 4480 2000 0 0
								11000 4480 1500 0 0
								11000 4490 1000 1 0>;
				strategy_temp_little_cool =	<11000 4480 4000 0 0
								11000 4480 3500 0 0
								11000 4480 3000 0 0
								11000 4480 2500 0 0
								11000 4480 2000 0 0
								11000 4480 1500 0 0
								11000 4490 1000 1 0>;
				strategy_temp_little_cool_high = <11000 4480 4000 0 0
								11000 4480 3500 0 0
								11000 4480 3000 0 0
								11000 4480 2500 0 0
								11000 4480 2000 0 0
								11000 4480 1500 0 0
								11000 4490 1000 1 0>;
				strategy_temp_normal_low =	<11000 4480 4000 0 0
								11000 4480 3500 0 0
								11000 4480 3000 0 0
								11000 4480 2500 0 0
								11000 4480 2000 0 0
								11000 4480 1500 0 0
								11000 4490 1000 1 0>;
				strategy_temp_normal_high =	<11000 4460 4000 0 0
								11000 4460 3500 0 0
								11000 4460 3000 0 0
								11000 4460 2500 0 0
								11000 4460 2000 0 0
								11000 4460 1500 0 0
								11000 4470 1000 1 0>;
				strategy_temp_warm =		<11000 4120 3200 0 0
								11000 4120 3000 0 0
								11000 4120 2500 0 0
								11000 4120 2000 0 0
								11000 4120 1500 0 0
								11000 4130 1000 1 0>;
			};
			strategy_soc_range_low {
				strategy_temp_little_cold =	<11000 4200 4000 0 0
								11000 4200 3500 0 0
								11000 4200 3000 0 0
								11000 4480 2900 0 0
								11000 4480 2500 0 0
								11000 4480 2000 0 0
								11000 4480 1500 0 0
								11000 4490 1000 1 0>;
				strategy_temp_cool =		<11000 4480 4000 0 0
								11000 4480 3500 0 0
								11000 4480 3000 0 0
								11000 4480 2500 0 0
								11000 4480 2000 0 0
								11000 4480 1500 0 0
								11000 4490 1000 1 0>;
				strategy_temp_little_cool =	<11000 4480 4000 0 0
								11000 4480 3500 0 0
								11000 4480 3000 0 0
								11000 4480 2500 0 0
								11000 4480 2000 0 0
								11000 4480 1500 0 0
								11000 4490 1000 1 0>;
				strategy_temp_little_cool_high = <11000 4480 4000 0 0
								11000 4480 3500 0 0
								11000 4480 3000 0 0
								11000 4480 2500 0 0
								11000 4480 2000 0 0
								11000 4480 1500 0 0
								11000 4490 1000 1 0>;
				strategy_temp_normal_low =	<11000 4480 4000 0 0
								11000 4480 3500 0 0
								11000 4480 3000 0 0
								11000 4480 2500 0 0
								11000 4480 2000 0 0
								11000 4480 1500 0 0
								11000 4490 1000 1 0>;
				strategy_temp_normal_high =	<11000 4460 4000 0 0
								11000 4460 3500 0 0
								11000 4460 3000 0 0
								11000 4460 2500 0 0
								11000 4460 2000 0 0
								11000 4460 1500 0 0
								11000 4470 1000 1 0>;
				strategy_temp_warm =		<11000 4120 3200 0 0
								11000 4120 3000 0 0
								11000 4120 2500 0 0
								11000 4120 2000 0 0
								11000 4120 1500 0 0
								11000 4130 1000 1 0>;
			};
			strategy_soc_range_mid_low {
				strategy_temp_little_cold =	<11000 4480 2000 0 0
								11000 4480 1500 0 0
								11000 4490 1000 1 0>;
				strategy_temp_cool =		<11000 4480 2500 0 0
								11000 4480 2000 0 0
								11000 4480 1500 0 0
								11000 4490 1000 1 0>;
				strategy_temp_little_cool =	<11000 4480 3000 0 0
								11000 4480 2500 0 0
								11000 4480 2000 0 0
								11000 4480 1500 0 0
								11000 4490 1000 1 0>;
				strategy_temp_little_cool_high = <11000 4480 3000 0 0
								11000 4480 2500 0 0
								11000 4480 2000 0 0
								11000 4480 1500 0 0
								11000 4490 1000 1 0>;
				strategy_temp_normal_low =	<11000 4480 4000 0 0
								11000 4480 3500 0 0
								11000 4480 3000 0 0
								11000 4480 2500 0 0
								11000 4480 2000 0 0
								11000 4480 1500 0 0
								11000 4490 1000 1 0>;
				strategy_temp_normal_high =	<11000 4460 4000 0 0
								11000 4460 3500 0 0
								11000 4460 3000 0 0
								11000 4460 2500 0 0
								11000 4460 2000 0 0
								11000 4460 1500 0 0
								11000 4470 1000 1 0>;
				strategy_temp_warm =		<11000 4120 3200 0 0
								11000 4120 3000 0 0
								11000 4120 2500 0 0
								11000 4120 2000 0 0
								11000 4120 1500 0 0
								11000 4130 1000 1 0>;
			};
			strategy_soc_range_mid {
				strategy_temp_little_cold =	<11000 4480 1500 0 0
								11000 4490 1000 1 0>;
				strategy_temp_cool =		<11000 4480 1500 0 0
								11000 4490 1000 1 0>;
				strategy_temp_little_cool =	<11000 4480 2000 0 0
								11000 4480 1500 0 0
								11000 4490 1000 1 0>;
				strategy_temp_little_cool_high = <11000 4480 2000 0 0
								11000 4480 1500 0 0
								11000 4490 1000 1 0>;
				strategy_temp_normal_low =	<11000 4480 2000 0 0
								11000 4480 1500 0 0
								11000 4490 1000 1 0>;
				strategy_temp_normal_high =	<11000 4460 2500 0 0
								11000 4460 2000 0 0
								11000 4460 1500 0 0
								11000 4470 1000 1 0>;
				strategy_temp_warm =		<11000 4130 1000 1 0>;
			};
			strategy_soc_range_mid_high {
				strategy_temp_little_cold =	<11000 4490 1000 1 0>;
				strategy_temp_cool =		<11000 4480 1500 0 0
								11000 4490 1000 1 0>;
				strategy_temp_little_cool =	<11000 4480 1500 0 0
								11000 4490 1000 1 0>;
				strategy_temp_little_cool_high = <11000 4480 1500 0 0
								11000 4490 1000 1 0>;
				strategy_temp_normal_low =	<11000 4480 1500 0 0
								11000 4490 1000 1 0>;
				strategy_temp_normal_high =	<11000 4460 1500 0 0
								11000 4470 1000 1 0>;
				strategy_temp_warm =		<11000 4130 1000 1 0>;
			};
			strategy_soc_range_high {
				strategy_temp_little_cold =	<11000 4490 1000 1 0>;
				strategy_temp_cool =		<11000 4490 1000 1 0>;
				strategy_temp_little_cool =	<11000 4490 1000 1 0>;
				strategy_temp_little_cool_high = <11000 4490 1000 1 0>;
				strategy_temp_normal_low =	<11000 4490 1000 1 0>;
				strategy_temp_normal_high =	<11000 4470 1000 1 0>;
				strategy_temp_warm =		<11000 4130 1000 1 0>;
			};
		};

		oplus,impedance_node {
			ufcs_input_impedance: ufcs_input_impedance {
				node_name = "ufcs_input";
				default_impedance_mohm = <0>;
				default_curr_ma = <4000>;
				current_drop_table = <
					250 4000
					340 3000
					380 2000
					480 0
				>;
			};
		};
	};

	oplus_virtual_dpdm_switch: oplus,virtual_dpdm_switch {
		compatible = "oplus,virtual_dpdm_switch";

		oplus,ic_type = <OPLUS_CHG_IC_MISC>;
		oplus,ic_index = <0>;

		oplus,use_audio_switch;
	};

	oplus_ufcs_impedance_check: oplus,ufcs_impedance_check {
		compatible = "oplus,impedance_check";

		oplus,impedance_unit {
			oplus_ufcs_impedance_unit: oplus,ufcs_impedance_unit {
				uint_name = "ufcs";
				default_curr_ma = <4000>;
				impedance_node = <&ufcs_input_impedance>;
			};
		};
	};
};

&qupv3_se13_2uart {
	pinctrl-1 = <&qupv3_se13_2uart_sleep_backup>;
	status = "okay";
};

&qupv3_se0_i2c_pins {

/*
	qupv3_se0_i2c_sda_active_oplus: qupv3_se0_i2c_sda_active_oplus {
		mux {
			pins = "gpio28";
			function = "qup1_se0_l0";
		};

		config {
			pins = "gpio28";
			drive-strength = <2>;
			bias-disable;
		};
	};

	qupv3_se0_i2c_scl_active_oplus: qupv3_se0_i2c_scl_active_oplus {
		mux {
			pins = "gpio29";
			function = "qup1_se0_l1";
		};

		config {
			pins = "gpio29";
			drive-strength = <2>;
			bias-disable;
		};
	};
*/

	qupv3_se0_i2c_pulldown: qupv3_se0_i2c_pulldown {
		mux {
			pins = "gpio28", "gpio29";
			function = "gpio";
		};

		config {
			pins = "gpio28", "gpio29";
			drive-strength = <2>;
			bias-pull-down;
			output-low;
		};
	};

	qupv3_se0_i2c_pullup: qupv3_se0_i2c_pullup {
		mux {
			pins = "gpio28", "gpio29";
			function = "gpio";
		};

		config {
			pins = "gpio28", "gpio29";
			drive-strength = <2>;
			bias-pull-up;
			input-enable;
		};
	};
};

&qupv3_se0_i2c {
	status = "ok";
	qcom,clk-freq-out = <100000>;
	pinctrl-names = "default", "sleep", "pulldown", "pullup";
	pinctrl-0 = <&qupv3_se0_i2c_sda_active>, <&qupv3_se0_i2c_scl_active>;
	pinctrl-1 = <&qupv3_se0_i2c_sleep>;
	pinctrl-2 = <&qupv3_se0_i2c_pulldown>;
	pinctrl-3 = <&qupv3_se0_i2c_pullup>;

	oplus_ext_gauge: bq27541-battery@55 {
		status = "okay";
		compatible = "oplus,bq27541-battery";
		reg = <0x55>;
		qcom,modify-soc-smooth;
		qcom,modify-soc-calibration;
		oplus,batt_nfg8011b;
		oplus,batt_num = <1>;
		oplus,ic_type = <OPLUS_CHG_IC_GAUGE>;
		oplus,ic_index = <0>;
		oplus,support_extern_cmd;
		oplus,calib_info_save_support;
	};
};

&tlmm {
	qupv3_se13_2uart_sleep_backup:qupv3_se13_2uart_sleep_backup {
		mux {
			pins = "gpio18", "gpio19";
			function = "gpio";
		};

		config {
			pins = "gpio18", "gpio19";
			drive-strength = <2>;
			bias-disable;
			input-enable;
		};
	};
	slave_charging_inter_active: slave_charging_inter_active {
		mux {
			pins = "gpio42";
			function = "gpio";
		};
		config {
			pins = "gpio42";
			bias-pull-up;
			drive-strength = <2>;
			input-enable;
		};
	};

	slave_charging_inter_sleep: slave_charging_inter_sleep {
		mux {
			pins = "gpio42";
			function = "gpio";
		};
		config {
			pins = "gpio42";
			bias-pull-up;
			drive-strength = <2>;
			input-enable;
		};
	};
};

&battery_charger {
	//for oplus chg framework:
	compatible = "oplus,hal_sm8350";
	oplus,chg_ops = "plat-pmic";
	qcom,pmic_ftm_vph = "/sys/bus/spmi/drivers/pmic-spmi/0-00/c42d000.qcom,spmi:qcom,pmk8550@0:vadc@9000/iio:device0/in_voltage_pm7550ba_vph_pwr_input";
	qcom,pmic_ftm_vbat = "/sys/bus/spmi/drivers/pmic-spmi/0-00/c42d000.qcom,spmi:qcom,pmk8550@0:vadc@9000/iio:device0/in_voltage_pm7550ba_vbat_sns_qbg_input";

	pinctrl-names = "subboard_temp_gpio_default";
	pinctrl-0 = <&subboard_temp_gpio_default>;

	qcom,otg_boost_src = <0>;//0:plat_pmic 1:external
	oplus,batt_num = <1>;
	oplus,otg_scheme = <0>;//0:cid 1:ccdetect_gpio 2:switch
	oplus_pm8550_charger: oplus,pm8550_charger {
		oplus,ic_type = <OPLUS_CHG_IC_BUCK>;
		oplus,ic_index = <0>;
	};

	oplus_adsp_gauge: oplus,adsp_gauge {
		oplus,ic_type = <OPLUS_CHG_IC_GAUGE>;
		oplus,ic_index = <1>;
	};

	oplus_adsp_pps: oplus,adsp_pps {
		oplus,ic_type = <OPLUS_CHG_IC_PPS>;
		oplus,ic_index = <0>;
	};
};

&battery_charger {
	io-channels = <&pmk8550_vadc PMXR2230_ADC5_GEN3_AMUX2_GPIO4_100K_PU>,
			<&pmk8550_vadc PMXR2230_ADC5_GEN3_AMUX1_GPIO3_100K_PU>,
			<&pmk8550_vadc PMXR2230_ADC5_GEN3_AMUX4_GPIO10_100K_PU>,
			<&pmk8550_vadc PMXR2230_ADC5_GEN3_AMUX_THM2_100K_PU>,
			<&pmk8550_vadc PM7550BA_ADC5_GEN3_AMUX_THM6_GPIO6_100K_PU>,
			<&pmk8550_vadc PMXR2230_ADC5_GEN3_AMUX_THM5_100K_PU>;
	io-channel-names = "usb_temp_adc_l", "usb_temp_adc_r", "subboard_temp_adc",
			"batt_con_therm_adc", "usb_con_therm_adc", "svooc_mos_btb_therm";
};

&qupv3_se3_i2c {
	status = "okay";
	qcom,clk-freq-out = <400000>;

	oplus_sc8547a:oplus,sc8547a@6F {
		status = "okay";
		compatible = "oplus,sc8547a";
		reg = <0x6F>;
		oplus,use_vooc_phy;
		oplus,use_ufcs_phy;
		oplus,vac_support;
		oplus,always_otg_en;

		oplus_spec,irq_gpio = <&tlmm 47 0x00>;

		pinctrl-names = "charging_inter_active", "charging_inter_sleep";
		pinctrl-0 = <&charging_inter_active>;
		pinctrl-1 = <&charging_inter_sleep>;

		oplus,ic_type = <OPLUS_CHG_IC_VPHY>;
		oplus,ic_index = <0>;
		oplus,vooc-version = <VOOC_VERSION_5_0>;

		oplus_spec,vooc_bad_volt = <3450 3400 3350 3300>;
		oplus_spec,vooc_bad_volt_suspend = <3450 3400 3350 3300>;
		oplus_spec,vooc_bad_volt_check_head_mask = /bits/ 8 <0x3>; /* VOOC 2.0/VOOC3.0 */
		oplus_spec,ap_control_allow;

		oplus_spec,external_gauge_support;
		oplus_spec,voocphy_current_default = <73>;

		oplus_spec,vooc_little_cold_full_voltage = <4570>;
		oplus_spec,vooc_cool_full_voltage = <4510>;
		oplus_spec,vooc_warm_full_voltage = <4130>;
		oplus_spec,vooc_1time_full_voltage = <4580>;
		oplus_spec,vooc_ntime_full_voltage = <4570>;
		oplus_spec,full_voltage = < /* vol_1time vol_ntime */
					4580 4570 /* 0 ~ 5 */
					4580 4510 /* 5 ~ 12 */
					4580 4570 /* 12 ~ 16 */
					4580 4570 /* 16 ~ 20 */
					4580 4570 /* 20 ~ 35 */
					4580 4570 /* 35 ~ 44 */
					4140 4130 /* 44 ~ 51 */
					>;

		ocp_reg = <0xe>;
		ovp_reg = <0x36>;
		oplus_spec,voocphy_dual_cp_support;
		oplus_spec,slave_cp_enable_thr = <1400>;
		oplus_spec,slave_cp_disable_thr_high = <1100>;
		oplus_spec,impedance_calculation_newmethod;
		oplus_spec,svooc_circuit_r_l = <0xa>;
		oplus_spec,svooc_circuit_r_h = <0x1>;

		oplus_spec,vooc_multistep_initial_batt_temp = <1000>;
		oplus_spec,vooc_little_cool_temp = <160>;
		oplus_spec,vooc_little_cool_high_temp = <210>;
		oplus_spec,vooc_cool_temp = <120>;
		oplus_spec,vooc_little_cold_temp = <50>;
		oplus_spec,vooc_normal_low_temp = <350>;
		oplus_spec,vooc_normal_to_little_cool_current = <100>;
		oplus_spec,vooc_over_high_temp = <510>;
		oplus_spec,vooc_low_temp = <50>;
		oplus_spec,vooc_high_temp = <500>;
		oplus_spec,vooc_low_soc = <0>;
		oplus_spec,vooc_high_soc = <90>;
		oplus_spec,vooc_normal_high_temp = <440>;
		oplus_spec,vooc_warm_vol_thr = <4000>;
		oplus_spec,vooc_warm_soc_thr = <55>;

		oplus_spec,fastchg_timeout_time_init = <150680>;
		oplus_spec,voocphy_ibat_over_current = <16000>;
		oplus_spec,voocphy_cp_max_ibus = <4500>;

		oplus_spec,voocphy_req_freq = <1996800 1996800 2246400 3513600>;
		oplus_spec,voocphy_freq_mincore = <1996800>;
		oplus_spec,voocphy_freq_midcore = <1996800>;
		oplus_spec,voocphy_freq_maxcore = <2246400>;
		oplus_spec,voocphy_current_change_timeout = <100>;
		oplus_spec,copycat_vooc_support;

		oplus_spec,soc_range = <0 20 35 55 75 85 90>;

		svooc_batt_sys_curve = <1 0 0 1 0 0 1	// 7300mA
					0 0 0 0 0 0 1	// 3414mV
					0 0 1 1 0 1 0	// 2600mA
					1 1 1 1 1 1 0	// 4664mV
					0 0 0 1 0 1 1	// 1100mA
					1 1 1 1 1 1 0>;	// 4664mV

		vooc_batt_sys_curve =  <0 1 1 1 1 0 0	// 6000mA
					0 0 0 0 0 0 1	// 3414mV
					0 0 1 1 0 1 0	// 2600mA
					1 1 1 1 1 1 0	// 4664mV
					0 0 0 1 0 1 1	// 1100mA
					1 1 1 1 1 1 0>;	// 4664mV

		svooc_lcf_strategy {
			oplus,temp_type = <OPLUS_STRATEGY_USE_SHELL_TEMP>;
			oplus,temp_range = <0 50 120 160 210 350 440>;

			strategy_temp_range_curves {
				strategy_temp_range_t0 =	<750  4570 0
								 700  4560 0
								 650  4550 0
								 600  4540 0
								 550  4530 1>;
				strategy_temp_range_t1 =	<850 4570 0
								 800  4565 0
								 750  4550 0
								 650  4540 0
								 550  4530 1>;
				strategy_temp_range_t2 =	<950 4570 0
								 900  4565 0
								 800  4550 0
								 700  4540 0
								 550  4530 1>;
				strategy_temp_range_t3 =	<1150 4570 0
								 1100 4565 0
								 1000 4550 0
								 900  4540 0
								 750  4530 1>;
				strategy_temp_range_t4 =	<1550 4570 0
								 1500 4565 0
								 1400 4550 0
								 1300 4540 0
								 1150 4530 1>;
				strategy_temp_range_t5 =	<2000 4534 0
								 1800 4518 0
								 1550 4511 0
								 1300 4505 0
								 1000 4495 1>;
			};
		};

		svooc_charge_strategy {
			strategy_soc_0_to_50 { /* 0 ~ 20 */
				strategy_temp_little_cold =	<4150 33 0 0 0
								 4150 30 0 0 0
								 4510 28 0 0 0
								 4510 25 0 0 0
								 4560 22 0 0 0
								 4560 20 0 0 0
								 4560 15 0 0 0
								 4570 10 1 0 0>;
				strategy_temp_cool =		<4150 25 0 0 0
								 4150 20 0 0 0
								 4500 15 0 0 0
								 4510 10 1 0 0>;
				strategy_temp_little_cool =	<4150 31 0 0 0
								 4150 30 0 0 0
								 4330 25 0 0 0
								 4330 20 0 0 0
								 4560 15 0 0 0
								 4570 10 1 0 0>;
				strategy_temp_little_cool_high =<4150 63 0 0 0
								 4150 61 0 0 0
								 4150 50 0 0 0
								 4280 47 0 0 0
								 4280 45 0 0 0
								 4280 40 0 0 0
								 4510 38 0 0 0
								 4510 35 0 0 0
								 4560 31 0 0 0
								 4560 30 0 0 0
								 4560 25 0 0 0
								 4560 20 0 0 0
								 4560 15 0 0 0
								 4570 10 1 0 0>;
				strategy_temp_normal_low =	<4130 73 0 60 0
								 4190 66 0 0 0
								 4250 57 0 0 0
								 4410 41 0 0 0
								 4410 40 0 0 0
								 4560 39 0 0 0
								 4560 35 0 0 0
								 4560 30 0 0 0
								 4560 25 0 0 0
								 4560 20 0 0 0
								 4560 15 0 0 0
								 4570 10 1 0 0>;
				strategy_temp_normal_high =	<4130 73 0 60 0
								 4190 66 0 0 0
								 4250 57 0 0 0
								 4410 41 0 0 0
								 4410 40 0 0 0
								 4560 39 0 0 0
								 4560 35 0 0 0
								 4560 30 0 0 0
								 4560 25 0 0 0
								 4560 20 0 0 0
								 4560 15 0 0 0
								 4565 11 1 0 0>;
				strategy_temp_warm =		<4120 18 0 0 0
								 4120 15 0 0 0
								 4130 10 1 0 0>;
			};

			strategy_soc_0_to_50_mid { /* 21 ~ 35 */
				strategy_temp_little_cold =	<4150 33 0 0 0
								 4150 30 0 0 0
								 4510 28 0 0 0
								 4510 25 0 0 0
								 4560 22 0 0 0
								 4560 20 0 0 0
								 4560 15 0 0 0
								 4570 10 1 0 0>;
				strategy_temp_cool =		<4150 25 0 0 0
								 4150 20 0 0 0
								 4500 15 0 0 0
								 4510 10 1 0 0>;
				strategy_temp_little_cool =	<4150 31 0 0 0
								 4150 30 0 0 0
								 4330 25 0 0 0
								 4330 20 0 0 0
								 4560 15 0 0 0
								 4570 10 1 0 0>;
				strategy_temp_little_cool_high =<4150 63 0 0 0
								 4150 61 0 0 0
								 4150 50 0 0 0
								 4280 47 0 0 0
								 4280 45 0 0 0
								 4280 40 0 0 0
								 4510 38 0 0 0
								 4510 35 0 0 0
								 4560 31 0 0 0
								 4560 30 0 0 0
								 4560 25 0 0 0
								 4560 20 0 0 0
								 4560 15 0 0 0
								 4570 10 1 0 0>;
				strategy_temp_normal_low =	<4130 73 0 60 0
								 4190 66 0 0 0
								 4250 57 0 0 0
								 4410 41 0 0 0
								 4410 40 0 0 0
								 4560 39 0 0 0
								 4560 35 0 0 0
								 4560 30 0 0 0
								 4560 25 0 0 0
								 4560 20 0 0 0
								 4560 15 0 0 0
								 4570 10 1 0 0>;
				strategy_temp_normal_high =	<4130 73 0 60 0
								 4190 66 0 0 0
								 4250 57 0 0 0
								 4410 41 0 0 0
								 4410 40 0 0 0
								 4560 39 0 0 0
								 4560 35 0 0 0
								 4560 30 0 0 0
								 4560 25 0 0 0
								 4560 20 0 0 0
								 4560 15 0 0 0
								 4565 11 1 0 0>;
				strategy_temp_warm =		<4120 18 0 0 0
								 4120 15 0 0 0
								 4130 10 1 0 0>;
			};

			strategy_soc_0_to_50_high { /* 36 ~ 55 */
				strategy_temp_little_cold =	<4560 20 0 0 0
								 4560 15 0 0 0
								 4570 10 1 0 0>;
				strategy_temp_cool =		<4150 25 0 0 0
								 4150 20 0 0 0
								 4500 15 0 0 0
								 4510 10 1 0 0>;
				strategy_temp_little_cool =	<4150 31 0 0 0
								 4150 30 0 0 0
								 4330 25 0 0 0
								 4330 20 0 0 0
								 4560 15 0 0 0
								 4570 10 1 0 0>;
				strategy_temp_little_cool_high =<4280 40 0 0 0
								 4510 38 0 0 0
								 4510 35 0 0 0
								 4560 31 0 0 0
								 4560 30 0 0 0
								 4560 25 0 0 0
								 4560 20 0 0 0
								 4560 15 0 0 0
								 4570 10 1 0 0>;
				strategy_temp_normal_low =	<4130 73 0 60 0
								 4190 66 0 0 0
								 4250 57 0 0 0
								 4410 41 0 0 0
								 4410 40 0 0 0
								 4560 39 0 0 0
								 4560 35 0 0 0
								 4560 30 0 0 0
								 4560 25 0 0 0
								 4560 20 0 0 0
								 4560 15 0 0 0
								 4570 10 1 0 0>;
				strategy_temp_normal_high =	<4130 73 0 60 0
								 4190 66 0 0 0
								 4250 57 0 0 0
								 4410 41 0 0 0
								 4410 40 0 0 0
								 4560 39 0 0 0
								 4560 35 0 0 0
								 4560 30 0 0 0
								 4560 25 0 0 0
								 4560 20 0 0 0
								 4560 15 0 0 0
								 4565 11 1 0 0>;
				strategy_temp_warm =		<4120 18 0 0 0
								 4120 15 0 0 0
								 4130 10 1 0 0>;
			};

			strategy_soc_50_to_75 { /* 56 ~ 75 */
				strategy_temp_little_cold =	<4560 15 0 0 0
								 4570 10 1 0 0>;
				strategy_temp_cool =		<4500 15 0 0 0
								 4510 10 1 0 0>;
				strategy_temp_little_cool =	<4330 20 0 0 0
								 4560 15 0 0 0
								 4570 10 1 0 0>;
				strategy_temp_little_cool_high =<4560 20 0 0 0
								 4560 15 0 0 0
								 4570 10 1 0 0>;
				strategy_temp_normal_low =	<4560 25 0 0 0
								 4560 20 0 0 0
								 4560 15 0 0 0
								 4570 10 1 0 0>;
				strategy_temp_normal_high =	<4560 30 0 0 0
								 4560 25 0 0 0
								 4560 20 0 0 0
								 4560 15 0 0 0
								 4565 11 1 0 0>;
				strategy_temp_warm =		<4120 16 0 0 0
								 4120 15 0 0 0
								 4130 10 1 0 0>;
			};

			strategy_soc_75_to_85 { /* 76 ~ 85 */
				strategy_temp_little_cold =	<4570 10 1 0 0>;
				strategy_temp_cool =		<4510 10 1 0 0>;
				strategy_temp_little_cool =	<4560 15 0 0 0
								 4570 10 1 0 0>;
				strategy_temp_little_cool_high =<4560 15 0 0 0
								 4570 10 1 0 0>;
				strategy_temp_normal_low =	<4560 15 0 0 0
								 4570 10 1 0 0>;
				strategy_temp_normal_high =	<4560 20 0 0 0
								 4560 15 0 0 0
								 4565 11 1 0 0>;
				strategy_temp_warm =		<4120 16 0 0 0
								 4120 15 0 0 0
								 4130 10 1 0 0>;
			};

			strategy_soc_85_to_90 { /* 86 ~ 95 */
				strategy_temp_little_cold =	<4570 10 1 0 0>;
				strategy_temp_cool =		<4510 10 1 0 0>;
				strategy_temp_little_cool =	<4570 10 1 0 0>;
				strategy_temp_little_cool_high =<4570 10 1 0 0>;
				strategy_temp_normal_low =	<4570 10 1 0 0>;
				strategy_temp_normal_high =	<4565 11 1 0 0>;
				strategy_temp_warm =		<4120 16 0 0 0
								 4120 15 0 0 0
								 4130 10 1 0 0>;
			};
		};

		vooc_charge_strategy {
			strategy_soc_0_to_50 { /* 0 ~ 20 */
				strategy_temp_little_cold =	<4150 60 0 0 0
								 4510 56 0 0 0
								 4510 50 0 0 0
								 4560 44 0 0 0
								 4560 40 0 0 0
								 4560 30 0 0 0
								 4570 20 1 0 0>;
				strategy_temp_cool =		<4150 50 0 0 0
								 4150 40 0 0 0
								 4500 30 0 0 0
								 4510 20 1 0 0>;
				strategy_temp_little_cool =	<4150 60 0 0 0
								 4330 50 0 0 0
								 4330 40 0 0 0
								 4560 30 0 0 0
								 4570 20 1 0 0>;
				strategy_temp_little_cool_high =<4560 60 0 0 0
								 4560 50 0 0 0
								 4560 40 0 0 0
								 4560 30 0 0 0
								 4570 20 1 0 0>;
				strategy_temp_normal_low =	<4560 60 0 0 0
								 4560 50 0 0 0
								 4560 40 0 0 0
								 4560 30 0 0 0
								 4565 22 1 0 0>;
				strategy_temp_normal_high =	<4560 60 0 0 0
								 4560 50 0 0 0
								 4560 40 0 0 0
								 4560 30 0 0 0
								 4570 20 1 0 0>;
				strategy_temp_warm =		<4120 36 0 0 0
								 4120 30 0 0 0
								 4130 20 1 0 0>;
			};

			strategy_soc_0_to_50_mid { /* 21 ~ 35 */
				strategy_temp_little_cold =	<4150 60 0 0 0
								 4510 56 0 0 0
								 4510 50 0 0 0
								 4560 44 0 0 0
								 4560 40 0 0 0
								 4560 30 0 0 0
								 4570 20 1 0 0>;
				strategy_temp_cool =		<4150 50 0 0 0
								 4150 40 0 0 0
								 4500 30 0 0 0
								 4510 20 1 0 0>;
				strategy_temp_little_cool =	<4150 60 0 0 0
								 4330 50 0 0 0
								 4330 40 0 0 0
								 4560 30 0 0 0
								 4570 20 1 0 0>;
				strategy_temp_little_cool_high =<4560 60 0 0 0
								 4560 50 0 0 0
								 4560 40 0 0 0
								 4560 30 0 0 0
								 4570 20 1 0 0>;
				strategy_temp_normal_low =	<4560 60 0 0 0
								 4560 50 0 0 0
								 4560 40 0 0 0
								 4560 30 0 0 0
								 4570 20 1 0 0>;
				strategy_temp_normal_high =	<4560 60 0 0 0
								 4560 50 0 0 0
								 4560 40 0 0 0
								 4560 30 0 0 0
								 4565 22 1 0 0>;
				strategy_temp_warm =		<4120 36 0 0 0
								 4120 30 0 0 0
								 4130 20 1 0 0>;
			};

			strategy_soc_0_to_50_high { /* 36 ~ 55 */
				strategy_temp_little_cold =	<4560 40 0 0 0
								 4560 30 0 0 0
								 4570 20 1 0 0>;
				strategy_temp_cool =		<4150 50 0 0 0
								 4150 40 0 0 0
								 4500 30 0 0 0
								 4510 20 1 0 0>;
				strategy_temp_little_cool =	<4150 60 0 0 0
								 4330 50 0 0 0
								 4330 40 0 0 0
								 4560 30 0 0 0
								 4570 20 1 0 0>;
				strategy_temp_little_cool_high =<4560 60 0 0 0
								 4560 50 0 0 0
								 4560 40 0 0 0
								 4560 30 0 0 0
								 4570 20 1 0 0>;
				strategy_temp_normal_low =	<4560 60 0 0 0
								 4560 50 0 0 0
								 4560 40 0 0 0
								 4560 30 0 0 0
								 4570 20 1 0 0>;
				strategy_temp_normal_high =	<4560 60 0 0 0
								 4560 50 0 0 0
								 4560 40 0 0 0
								 4560 30 0 0 0
								 4565 22 1 0 0>;
				strategy_temp_warm =		<4120 36 0 0 0
								 4120 30 0 0 0
								 4130 20 1 0 0>;
			};

			strategy_soc_50_to_75 { /* 56 ~ 75 */
				strategy_temp_little_cold =	<4560 30 0 0 0
								 4570 20 1 0 0>;
				strategy_temp_cool =		<4500 30 0 0 0
								 4510 20 1 0 0>;
				strategy_temp_little_cool =	<4330 40 0 0 0
								 4560 30 0 0 0
								 4570 20 1 0 0>;
				strategy_temp_little_cool_high =<4560 40 0 0 0
								 4560 30 0 0 0
								 4570 20 1 0 0>;
				strategy_temp_normal_low =	<4560 50 0 0 0
								 4560 40 0 0 0
								 4560 30 0 0 0
								 4570 20 1 0 0>;
				strategy_temp_normal_high =	<4560 60 0 0 0
								 4560 50 0 0 0
								 4560 40 0 0 0
								 4560 30 0 0 0
								 4565 22 1 0 0>;
				strategy_temp_warm =		<4120 32 0 0 0
								 4120 30 0 0 0
								 4130 20 1 0 0>;
			};

			strategy_soc_75_to_85 { /* 76 ~ 85 */
				strategy_temp_little_cold =	<4570 20 1 0 0>;
				strategy_temp_cool =		<4510 20 1 0 0>;
				strategy_temp_little_cool =	<4560 30 0 0 0
								 4570 20 1 0 0>;
				strategy_temp_little_cool_high =<4560 30 0 0 0
								 4570 20 1 0 0>;
				strategy_temp_normal_low =	<4560 30 0 0 0
								 4570 20 1 0 0>;
				strategy_temp_normal_high =	<4560 40 0 0 0
								 4560 30 0 0 0
								 4565 22 1 0 0>;
				strategy_temp_warm =		<4120 32 0 0 0
								 4120 30 0 0 0
								 4130 20 1 0 0>;
			};

			strategy_soc_85_to_90 { /* 86 ~ 95 */
				strategy_temp_little_cold =	<4570 20 1 0 0>;
				strategy_temp_cool =		<4510 20 1 0 0>;
				strategy_temp_little_cool =	<4570 20 1 0 0>;
				strategy_temp_little_cool_high =<4570 20 1 0 0>;
				strategy_temp_normal_low =	<4570 20 1 0 0>;
				strategy_temp_normal_high =	<4565 22 1 0 0>;
				strategy_temp_warm =		<4120 32 0 0 0
								 4120 30 0 0 0
								 4130 20 1 0 0>;
			};
		};
		oplus_sc8547_cp: oplus,sc8547_cp {
			oplus,ic_type = <OPLUS_CHG_IC_CP>;
			oplus,ic_index = <0>;
			oplus,ic_func_group = <&sc8547_cp_groups>;
		};
	};
};

&soc {
	oplus_virtual_pps: oplus,virtual_pps {
		compatible = "oplus,virtual_pps";

		oplus,ic_type = <OPLUS_CHG_IC_VIRTUAL_PPS>;
		oplus,ic_index = <0>;
		oplus,pps_ic = <&oplus_adsp_pps>;
	};
	oplus_pps_charge: oplus,pps_charge {
		compatible = "oplus,pps_charge";
		oplus,pps_ic = <&oplus_virtual_pps>;
		oplus,cp_ic = <&oplus_virtual_cp>;
		oplus,dpdm_switch_ic = <&oplus_virtual_dpdm_switch>;

		// oplus,impedance_unit = <&oplus_pps_impedance_unit>;

		oplus,target_vbus_mv = <11000>;
		oplus,curr_max_ma = <3000>;

		oplus,pps_warm_allow_vol = <4000>;
		oplus,pps_warm_allow_soc = <50>;
		oplus,pps_strategy_normal_current = <3000>;
		oplus,pps_over_high_or_low_current = <3000>;
		oplus,pps_timeout_third = <17562>;
		oplus,pps_timeout_oplus = <17562>;
		oplus,pps_ibat_over_third = <7400>;
		oplus,pps_ibat_over_oplus = <7400>;
		oplus,pps_full_cool_sw_vbat = <4500>;
		oplus,pps_full_normal_sw_vbat = <4500>;
		oplus,pps_full_normal_hw_vbat = <4510>;
		oplus,pps_full_ffc_vbat = <4520>;
		oplus,pps_full_warm_vbat = <4130>;
		oplus,pps_full_cool_sw_vbat_third = <4500>;
		oplus,pps_full_normal_sw_vbat_third= <4500>;
		oplus,pps_full_normal_hw_vbat_third = <4510>;
		oplus,pps_current_change_timeout = <100>;
		oplus,pps_r_default = <270 45 10 45 20 20 20>;
		oplus,pps_rmos_mohm = <5>;
		oplus,pps_r_limit = <150 100 80 70 30>;
		oplus,pps_strategy_batt_high_temp = <410 420 430 400 410 420>;
		oplus,pps_strategy_high_current = <3000 2000 2000 3000 3000 3000>;
		oplus,pps_charge_strategy_soc = <0 20 35 50 75 85 85>;
		oplus,pps_charge_strategy_temp = <50 50 120 160 350 440 510>;
		oplus,pps_little_cool_high_temp = <210>;
		oplus,pps_low_curr_full_strategy_temp = <0 200 350 440>;
		oplus,curve_strategy_name = "pps_ufcs_curve_v2";
		oplus,plc_strategy-data = <&pps_simple_strategy>;
		oplus,plc_strategy-names = "default";

		oplus,temperature_strategy_name = "cgcl";
		oplus,temperature_strategy_data = <OPLUS_STRATEGY_USE_SHELL_TEMP
						0   385 7300 1 0
						375 405 5000 2 0
						395 420 4000 3 1
						410 430 3500 4 2
						420 440 2000 4 3>;

		pps_charge_low_curr_full {
			strategy_temp_little_cool = 	<1500 4490 0
							 1400 4480 0
							 1300 4470 0
							 1200 4460 0
							 1100 4450 1>;
			strategy_temp_normal_low =	<1500 4490 0
                                                         1400 4480 0
                                                         1300 4470 0
                                                         1200 4460 0
                                                         1100 4450 1>;
			strategy_temp_normal_high = 	<1600 4490 0
                                                         1400 4480 0
                                                         1300 4470 0
                                                         1200 4460 0
                                                         1100 4450 1>;
		};

		pps_charge_third_strategy {
			oplus,temp_type = <OPLUS_STRATEGY_USE_SHELL_TEMP>;
			oplus,soc_range = <0 20 35 55 75 85 90>;
			oplus,temp_range = <0 50 120 160 210 350 440 510>;

			strategy_soc_range_min {/* 0 ~ 20 */
				strategy_temp_little_cold =	<11000 4200 2500 0 0
								11000 4455 2000 0 0
								11000 4455 1500 0 0
								11000 4465 1000 1 0>;
				strategy_temp_cool =		<11000 4150 2500 0 0
								11000 4150 2000 0 0
								11000 4490 1500 0 0
								11000 4500 1000 1 0>;
				strategy_temp_little_cool =	<11000 4150 3000 0 0
								11000 4330 2500 0 0
								11000 4330 2000 0 0
								11000 4490 1500 0 0
								11000 4500 1000 1 0>;
				strategy_temp_little_cool_high = <11000 4150 3000 0 0
								11000 4330 2500 0 0
								11000 4330 2000 0 0
								11000 4490 1500 0 0
								11000 4500 1000 1 0>;
				strategy_temp_normal_low =	<11000 4490 3000 0 0
								11000 4490 2500 0 0
								11000 4490 2000 0 0
								11000 4490 1500 0 0
								11000 4500 1000 1 0>;
				strategy_temp_normal_high =	<11000 4465 3000 0 0
								11000 4465 2500 0 0
								11000 4465 2000 0 0
								11000 4465 1500 0 0
								11000 4475 1000 1 0>;
				strategy_temp_warm =		<11000 4120 1850 0 0
								11000 4120 1500 0 0
								11000 4130 1000 0 0>;
			};
			strategy_soc_range_low {/* 21 ~ 35 */
				strategy_temp_little_cold =	<11000 4200 2500 0 0
								11000 4455 2000 0 0
								11000 4455 1500 0 0
								11000 4465 1000 1 0>;
				strategy_temp_cool =		<11000 4150 2500 0 0
								11000 4150 2000 0 0
								11000 4490 1500 0 0
								11000 4500 1000 1 0>;
				strategy_temp_little_cool =	<11000 4150 3000 0 0
								11000 4330 2500 0 0
								11000 4330 2000 0 0
								11000 4490 1500 0 0
								11000 4500 1000 1 0>;
				strategy_temp_little_cool_high = <11000 4490 3000 0 0
								11000 4490 2500 0 0
								11000 4490 2000 0 0
								11000 4490 1500 0 0
								11000 4500 1000 1 0>;
				strategy_temp_normal_low =	<11000 4490 3000 0 0
								11000 4490 2500 0 0
								11000 4490 2000 0 0
								11000 4490 1500 0 0
								11000 4500 1000 1 0>;
				strategy_temp_normal_high =	<11000 4465 3000 0 0
								11000 4465 2500 0 0
								11000 4465 2000 0 0
								11000 4465 1500 0 0
								11000 4475 1000 1 0>;
				strategy_temp_warm =		<11000 4120 1850 0 0
								11000 4120 1500 0 0
								11000 4130 1000 1 0>;
			};
			strategy_soc_range_mid_low {/* 36 ~ 55 */
				strategy_temp_little_cold =	<11000 4200 2500 0 0
								11000 4455 2000 0 0
								11000 4455 1500 0 0
								11000 4465 1000 1 0>;
				strategy_temp_cool =		<11000 4150 2500 0 0
								11000 4150 2000 0 0
								11000 4490 1500 0 0
								11000 4500 1000 1 0>;
				strategy_temp_little_cool =	<11000 4150 3000 0 0
								11000 4330 2500 0 0
								11000 4330 2000 0 0
								11000 4490 1500 0 0
								11000 4500 1000 1 0>;
				strategy_temp_little_cool_high = <11000 4490 3000 0 0
								11000 4490 2500 0 0
								11000 4490 2000 0 0
								11000 4490 1500 0 0
								11000 4500 1000 1 0>;
				strategy_temp_normal_low =	<11000 4490 3000 0 0
								11000 4490 2500 0 0
								11000 4490 2000 0 0
								11000 4490 1500 0 0
								11000 4500 1000 1 0>;
				strategy_temp_normal_high =	<11000 4465 3000 0 0
								11000 4465 2500 0 0
								11000 4465 2000 0 0
								11000 4465 1500 0 0
								11000 4475 1000 1 0>;
				strategy_temp_warm =		<11000 4120 1850 0 0
								11000 4120 1500 0 0
								11000 4130 1000 0 0>;
			};
			strategy_soc_range_mid {/* 56 ~ 75 */
				strategy_temp_little_cold =	<11000 4200 2500 0 0
								11000 4455 2000 0 0
								11000 4455 1500 0 0
								11000 4465 1000 1 0>;
				strategy_temp_cool =		<11000 4490 1500 0 0
								11000 4500 1000 1 0>;
				strategy_temp_little_cool =	<11000 4330 2000 0 0
								11000 4490 1500 0 0
								11000 4500 1000 1 0>;
				strategy_temp_little_cool_high = <11000 4490 2000 0 0
								11000 4490 1500 0 0
								11000 4500 1000 1 0>;
				strategy_temp_normal_low =	<11000 4490 2000 0 0
								11000 4490 1500 0 0
								11000 4500 1000 1 0>;
				strategy_temp_normal_high =	<11000 4465 2500 0 0
								11000 4465 2000 0 0
								11000 4465 1500 0 0
								11000 4475 1000 1 0>;
				strategy_temp_warm =		<11000 4130 1000 1 0>;
			};
			strategy_soc_range_mid_high {/* 76 ~ 85 */
				strategy_temp_little_cold =	<11000 4455 2000 0 0
								11000 4455 1500 0 0
								11000 4465 1000 1 0>;
				strategy_temp_cool =		<11000 4500 1000 1 0>;
				strategy_temp_little_cool =	<11000 4500 1000 1 0>;
				strategy_temp_little_cool_high = <11000 4500 1000 1 0>;
				strategy_temp_normal_low =	<11000 4490 1500 0 0
								11000 4500 1000 1 0>;
				strategy_temp_normal_high =	<11000 4465 1500 0 0
								11000 4475 1000 1 0>;
				strategy_temp_warm =		<11000 4130 1000 1 0>;
			};
			strategy_soc_range_high {/* 86 ~ 90 */
				strategy_temp_little_cold =	<11000 4465 2000 0 0
								11000 4465 1500 0 0
								11000 4465 1000 1 0>;
				strategy_temp_cool =		<11000 4455 2500 0 0
								11000 4455 2000 0 0
								11000 4455 1500 0 0
								11000 4465 1000 1 0>;
				strategy_temp_little_cool =	<11000 4460 2000 0 0
								11000 4460 1500 0 0
								11000 4470 1000 1 0>;
				strategy_temp_little_cool_high = <11000 4480 3000 0 0
								11000 4480 2500 0 0
								11000 4480 2000 0 0
								11000 4480 1500 0 0
								11000 4490 1000 1 0>;
				strategy_temp_normal_low =	<11000 4460 3000 0 0
								11000 4460 2500 0 0
								11000 4460 2000 0 0
								11000 4460 1500 0 0
								11000 4470 1000 1 0>;
				strategy_temp_normal_high =	<11000 4460 3000 0 0
								11000 4460 2500 0 0
								11000 4460 2000 0 0
								11000 4460 1500 0 0
								11000 4470 1000 1 0>;
				strategy_temp_warm =		<11000 4130 1100 1 0>;
			};
		};

		pps_charge_oplus_strategy {
			oplus,temp_type = <OPLUS_STRATEGY_USE_SHELL_TEMP>;
			oplus,soc_range = <0 20 35 55 75 85 90>;
			oplus,temp_range = <0 50 120 160 210 350 440 530>;


			strategy_soc_range_min {
				strategy_temp_little_cold =	<11000 4200 2500 0 0
								11000 4455 2000 0 0
								11000 4455 1500 0 0
								11000 4465 1000 1 0>;
				strategy_temp_cool =		<11000 4180 4000 0 0
								11000 4455 3000 0 0
								11000 4455 2500 0 0
								11000 4455 2000 0 0
								11000 4455 1500 0 0
								11000 4465 1000 1 0>;
				strategy_temp_little_cool =	<11000 4200 5000 0 0
								11000 4400 3000 0 0
								11000 4400 2500 0 0
								11000 4460 2000 0 0
								11000 4460 1500 0 0
								11000 4470 1000 1 0>;
				strategy_temp_little_cool_high = <11000 4480 3000 0 0
								11000 4480 2500 0 0
								11000 4480 2000 0 0
								11000 4480 1500 0 0
								11000 4490 1000 1 0>;
				strategy_temp_normal_low =	<11000 4250 5000 0 0
								11000 4250 4500 0 0
								11000 4400 4150 0 0
								11000 4400 4000 0 0
								11000 4490 3900 0 0
								11000 4490 3500 0 0
								11000 4490 3000 0 0
								11000 4490 2500 0 0
								11000 4490 2000 0 0
								11000 4490 1500 0 0
								11000 4500 1000 1 0>;
				strategy_temp_normal_high =	<11000 4250 5000 0 0
								11000 4400 4000 0 0
								11000 4460 3000 0 0
								11000 4460 2500 0 0
								11000 4460 2000 0 0
								11000 4460 1500 0 0
								11000 4470 1000 1 0>;
				strategy_temp_warm =		<11000 4130 1000 1 0>;
			};
			strategy_soc_range_low {
				strategy_temp_little_cold =	<11000 4200 2500 0 0
								11000 4455 2000 0 0
								11000 4455 1500 0 0
								11000 4465 1000 1 0>;
				strategy_temp_cool =		<11000 4180 4000 0 0
								11000 4455 3000 0 0
								11000 4455 2500 0 0
								11000 4455 2000 0 0
								11000 4455 1500 0 0
								11000 4465 1000 1 0>;
				strategy_temp_little_cool =	<11000 4200 5000 0 0
								11000 4400 3000 0 0
								11000 4400 2500 0 0
								11000 4460 2000 0 0
								11000 4460 1500 0 0
								11000 4470 1000 1 0>;
				strategy_temp_little_cool_high = <11000 4480 3000 0 0
								11000 4480 2500 0 0
								11000 4480 2000 0 0
								11000 4480 1500 0 0
								11000 4490 1000 1 0>;
				strategy_temp_normal_low =	<11000 4250 5000 0 0
								11000 4250 4500 0 0
								11000 4400 4150 0 0
								11000 4400 4000 0 0
								11000 4490 3900 0 0
								11000 4490 3500 0 0
								11000 4490 3000 0 0
								11000 4490 2500 0 0
								11000 4490 2000 0 0
								11000 4490 1500 0 0
								11000 4500 1000 1 0>;
				strategy_temp_normal_high =	<11000 4250 5000 0 0
								11000 4400 4000 0 0
								11000 4460 3000 0 0
								11000 4460 2500 0 0
								11000 4460 2000 0 0
								11000 4460 1500 0 0
								11000 4470 1000 1 0>;
				strategy_temp_warm =		<11000 4130 1000 1 0>;
			};
			strategy_soc_range_mid_low {
				strategy_temp_little_cold =	<11000 4200 2500 0 0
								11000 4455 2000 0 0
								11000 4455 1500 0 0
								11000 4465 1000 1 0>;
				strategy_temp_cool =		<11000 4180 4000 0 0
								11000 4455 3000 0 0
								11000 4455 2500 0 0
								11000 4455 2000 0 0
								11000 4455 1500 0 0
								11000 4465 1000 1 0>;
				strategy_temp_little_cool =	<11000 4200 5000 0 0
								11000 4400 3000 0 0
								11000 4400 2500 0 0
								11000 4460 2000 0 0
								11000 4460 1500 0 0
								11000 4470 1000 1 0>;
				strategy_temp_little_cool_high = <11000 4480 3000 0 0
								11000 4480 2500 0 0
								11000 4480 2000 0 0
								11000 4480 1500 0 0
								11000 4490 1000 1 0>;
				strategy_temp_normal_low =	<11000 4250 5000 0 0
								11000 4250 4500 0 0
								11000 4400 4150 0 0
								11000 4400 4000 0 0
								11000 4490 3900 0 0
								11000 4490 3500 0 0
								11000 4490 3000 0 0
								11000 4490 2500 0 0
								11000 4490 2000 0 0
								11000 4490 1500 0 0
								11000 4500 1000 1 0>;
				strategy_temp_normal_high =	<11000 4250 5000 0 0
								11000 4400 4000 0 0
								11000 4460 3000 0 0
								11000 4460 2500 0 0
								11000 4460 2000 0 0
								11000 4460 1500 0 0
								11000 4470 1000 1 0>;
				strategy_temp_warm =		<11000 4130 1000 1 0>;
			};
			strategy_soc_range_mid {
				strategy_temp_little_cold =	<11000 4200 2500 0 0
								11000 4455 2000 0 0
								11000 4455 1500 0 0
								11000 4465 1000 1 0>;
				strategy_temp_cool =		<11000 4180 4000 0 0
								11000 4455 3000 0 0
								11000 4455 2500 0 0
								11000 4455 2000 0 0
								11000 4455 1500 0 0
								11000 4465 1000 1 0>;
				strategy_temp_little_cool =	<11000 4200 5000 0 0
								11000 4400 3000 0 0
								11000 4400 2500 0 0
								11000 4460 2000 0 0
								11000 4460 1500 0 0
								11000 4470 1000 1 0>;
				strategy_temp_little_cool_high = <11000 4480 3000 0 0
								11000 4480 2500 0 0
								11000 4480 2000 0 0
								11000 4480 1500 0 0
								11000 4490 1000 1 0>;
				strategy_temp_normal_low =	<11000 4490 2000 0 0
								11000 4490 2000 0 0
								11000 4450 1000 1 0>;
				strategy_temp_normal_high =	<11000 4250 5000 0 0
								11000 4400 4000 0 0
								11000 4460 3000 0 0
								11000 4460 2500 0 0
								11000 4460 2000 0 0
								11000 4460 1500 0 0
								11000 4470 1000 1 0>;
				strategy_temp_warm =		<11000 4130 1000 1 0>;
			};
			strategy_soc_range_mid_high {
				strategy_temp_little_cold =	<11000 4455 2000 0 0
								11000 4455 1500 0 0
								11000 4465 1000 1 0>;
				strategy_temp_cool =		<11000 4400 3000 0 0
								11000 4400 2500 0 0
								11000 4455 2000 0 0
								11000 4455 1500 0 0
								11000 4465 1000 1 0>;
				strategy_temp_little_cool =	<11000 4400 3000 0 0
								11000 4400 2500 0 0
								11000 4460 2000 0 0
								11000 4460 1500 0 0
								11000 4470 1000 1 0>;
				strategy_temp_little_cool_high = <11000 4480 3000 0 0
								11000 4480 2500 0 0
								11000 4480 2000 0 0
								11000 4480 1500 0 0
								11000 4490 1000 1 0>;
				strategy_temp_normal_low =	<11000 4490 1500 0 0
								11000 4450 1000 1 0>;
				strategy_temp_normal_high =	<11000 4400 4000 0 0
								11000 4460 3000 0 0
								11000 4460 2500 0 0
								11000 4460 2000 0 0
								11000 4460 1500 0 0
								11000 4470 1000 1 0>;
				strategy_temp_warm =		<11000 4130 1000 1 0>;
			};
			strategy_soc_range_high {
				strategy_temp_little_cold =	<11000 4465 2000 0 0
								11000 4465 1500 0 0
								11000 4465 1000 1 0>;
				strategy_temp_cool =		<11000 4455 2500 0 0
								11000 4455 2000 0 0
								11000 4455 1500 0 0
								11000 4465 1000 1 0>;
				strategy_temp_little_cool =	<11000 4460 2000 0 0
								11000 4460 1500 0 0
								11000 4470 1000 1 0>;
				strategy_temp_little_cool_high = <11000 4480 3000 0 0
								11000 4480 2500 0 0
								11000 4480 2000 0 0
								11000 4480 1500 0 0
								11000 4490 1000 1 0>;
				strategy_temp_normal_low =	<11000 4460 3000 0 0
								11000 4460 2500 0 0
								11000 4460 2000 0 0
								11000 4460 1500 0 0
								11000 4470 1000 1 0>;
				strategy_temp_normal_high =	<11000 4460 3000 0 0
								11000 4460 2500 0 0
								11000 4460 2000 0 0
								11000 4460 1500 0 0
								11000 4470 1000 1 0>;
				strategy_temp_warm =		<11000 4130 1100 1 0>;
			};
		};
	};
};

&qupv3_se4_i2c {
	status = "okay";
	clock-frequency = <400000>;
	oplus_sc8547_slave: sc8547-charger-slave@6F{
		status = "okay";
		compatible = "slave_vphy_sc8547";
		reg = <0x6F>;
		ocp_reg = <0xe>;
		ovp_reg = <0x36>;
		oplus,use_slave_cp;

		oplus_spec,irq_gpio = <&tlmm 42 0x00>;

		pinctrl-names = "charging_inter_active", "charging_inter_sleep";
		pinctrl-0 = <&slave_charging_inter_active>;
		pinctrl-1 = <&slave_charging_inter_sleep>;

		oplus_sc8547_slave_cp: oplus,sc8547_slave_cp {
			oplus,ic_type = <OPLUS_CHG_IC_CP>;
			oplus,ic_index = <1>;
			oplus,ic_func_group = <&sc8547_cp_groups>;
		};
	};
};

&tlmm {
	charging_inter_active: charging_inter_active {
		mux {
			pins = "gpio47";
			function = "gpio";
		};
		config {
			pins = "gpio47";
			bias-pull-up; /* NO pull */
			drive-strength = <2>; /* 2 MA */
			input-enable;
		};
	};

	charging_inter_sleep: charging_inter_sleep {
		mux {
			pins = "gpio47";
			function = "gpio";
		};
		config {
			pins = "gpio47";
			bias-pull-up; /* NO pull */
			drive-strength = <2>; /* 2 MA */
			input-enable;
		};
	};
};

&pm7550ba_gpios {
	usb_con_therm_adc_default: usb_con_therm_adc_default {
		pins = "gpio6";
		function = "normal"; //normal
		bias-high-impedance;
		bias-disable;
	};
};

&pmxr2230_gpios {
	usbtemp_l_gpio_default: usbtemp_l_gpio_default {
		pins = "gpio4"; //GPIO 4
		function = "normal"; //normal
		bias-high-impedance; //DISABLE GPIO5 for ADC
		bias-disable;
	};
	usbtemp_r_gpio_default: usbtemp_r_gpio_default {
		pins = "gpio3"; //GPIO 3
		function = "normal"; //normal
		bias-high-impedance; //DISABLE GPIO10 for ADC
		bias-disable;
	};
	subboard_temp_gpio_default: subboard_temp_gpio_default {
		pins = "gpio10"; //GPIO 10
		function = "normal"; //normal
		bias-high-impedance; //DISABLE GPIO4 for ADC
		bias-disable;
	};

	dischg_enable: dischg_enable {
		pins = "gpio9";
		function = "normal";
		bias-disable;
		output-high;
	};

	dischg_disable: dischg_disable {
		pins = "gpio9";
		function = "normal";
		bias-disable;
		output-low;
	};
};
&pmk8550_vadc {
	pinctrl-0 = <&usb_con_therm_adc_default>;
	pinctrl-names = "default";

	usb_temp_adc_l {
		reg = <PMXR2230_ADC5_GEN3_AMUX2_GPIO4_100K_PU>;
		label = "usb_temp_adc_l";
		qcom,pre-scaling = <1 1>;
		qcom,hw-settle-time = <200>;
		qcom,scale-fn-type = <OPLUS_ADC_SCALE_HW_CALIB_DEFAULT>;
	};
	usb_temp_adc_r {
		reg = <PMXR2230_ADC5_GEN3_AMUX1_GPIO3_100K_PU>;
		label = "usb_temp_adc_r";
		qcom,pre-scaling = <1 1>;
		qcom,hw-settle-time = <200>;
		qcom,scale-fn-type = <OPLUS_ADC_SCALE_HW_CALIB_DEFAULT>;
	};

	subboard_temp_adc {
		reg = <PMXR2230_ADC5_GEN3_AMUX4_GPIO10_100K_PU>;
		label = "subboard_temp_adc";
		qcom,pre-scaling = <1 1>;
		qcom,ratiometric;
		qcom,hw-settle-time = <200>;
	};

	batt_con_therm_adc {
		reg = <PMXR2230_ADC5_GEN3_AMUX_THM2_100K_PU>;
		label = "batt_con_therm_adc";
		qcom,ratiometric;
		qcom,hw-settle-time = <200>;
		qcom,pre-scaling = <1 1>;
		qcom,adc-tm-type = <0>;
	};
	usb_con_therm_adc {
		reg = <PM7550BA_ADC5_GEN3_AMUX_THM6_GPIO6_100K_PU>;
		label = "usb_con_therm_adc";
		qcom,ratiometric;
		qcom,hw-settle-time = <200>;
		qcom,pre-scaling = <1 1>;
		qcom,adc-tm-type = <0>;
	};

	svooc_mos_btb_therm {
		reg = <PMXR2230_ADC5_GEN3_AMUX_THM5_100K_PU>;
		label = "svooc_mos_btb_therm";
		qcom,ratiometric;
		qcom,hw-settle-time = <200>;
		qcom,pre-scaling = <1 1>;
		qcom,adc-tm-type = <1>;
	};

	pm7550ba_vbat_sns_qbg {
		reg = <PM7550BA_ADC5_GEN3_VBAT_SNS_QBG>;
		label = "pm7550ba_vbat_sns_qbg";
		qcom,pre-scaling = <1 3>;
	};
};

&thermal_zones {
	svooc_mos_btb_usr {
		polling-delay-passive = <0>;
		polling-delay = <0>;
		thermal-governor = "user_space";
		thermal-sensors = <&pmk8550_vadc PMXR2230_ADC5_GEN3_AMUX_THM5_100K_PU>;
		wake-capable-sensor;
		trips {
			active-config0 {
				temperature = <125000>;
				hysteresis = <1000>;
				type = "passive";
			};
		};
	};
};

&ibat_lvl0 {
	temperature = <12000>;
};

&ibat_lvl1 {
	temperature = <12000>;
};
